[part 1 of 3: packages /MICROSAR/Dem_swc/DataTypes to /MICROSAR/Dem_swc/ComponentTypes]
AUTOSAR XML (schema 00048)
package /MICROSAR/Dem_swc/DataTypes
  25 x impl type:
    Dem_EventIdType: range raw 1..65535, implementation-data-type=uint16
    Dem_RatioIdType: range raw 1..65535, implementation-data-type=uint16
    Dem_DTCStatusMaskType: range raw 0..255, implementation-data-type=uint8
    Dem_OperationCycleIdType: range raw 0..255, implementation-data-type=uint8
    Dem_DTCGroupType: range raw 0..16777215, implementation-data-type=uint32
    Dem_MaxDataValueType: category=ARRAY, sw-calibration-access=READ-ONLY
      element Dem_MaxDataValueTypeElement: array-size=8, array-size-semantics=FIXED-SIZE, implementation-data-type=uint8
    Dem_EventStatusType:
      compu {0=DEM_EVENT_STATUS_PASSED, 1=DEM_EVENT_STATUS_FAILED, 2=DEM_EVENT_STATUS_PREPASSED, 3=DEM_EVENT_STATUS_PREFAILED, 4=DEM_EVENT_STATUS_FDC_THRESHOLD_REACHED, 5=DEM_EVENT_STATUS_PASSED_CONDITIONS_NOT_FULFILLED, 6=DEM_EVENT_STATUS_FAILED_CONDITIONS_NOT_FULFILLED, 7=DEM_EVENT_STATUS_PREPASSED_CONDITIONS_NOT_FULFILLED, 8=DEM_EVENT_STATUS_PREFAILED_CONDITIONS_NOT_FULFILLED}
      range raw 0..255
      implementation-data-type=uint8
    Dem_InitMonitorReasonType: compu {1=DEM_INIT_MONITOR_CLEAR, 2=DEM_INIT_MONITOR_RESTART, 3=DEM_INIT_MONITOR_REENABLED, 4=DEM_INIT_MONITOR_STORAGE_REENABLED}, range raw 1..4, implementation-data-type=uint8
    Dem_DTCOriginType:
      compu {1=DEM_DTC_ORIGIN_PRIMARY_MEMORY, 2=DEM_DTC_ORIGIN_MIRROR_MEMORY, 3=DEM_DTC_ORIGIN_PERMANENT_MEMORY, 4=DEM_DTC_ORIGIN_OBD_RELEVANT_MEMORY, 5=DEM_DTC_ORIGIN_SECONDARY_MEMORY, 5=DEM_DTC_ORIGIN_USERDEFINED_MEMORY_10, 5=DEM_DTC_ORIGIN_USERDEFINED_MEMORY_11, 5=DEM_DTC_ORIGIN_USERDEFINED_MEMORY_12, 5=DEM_DTC_ORIGIN_USERDEFINED_MEMORY_13, 5=DEM_DTC_ORIGIN_USERDEFINED_MEMORY_14, 5=DEM_DTC_ORIGIN_USERDEFINED_MEMORY_15, 5=DEM_DTC_ORIGIN_USERDEFINED_MEMORY_16, 5=DEM_DTC_ORIGIN_USERDEFINED_MEMORY_17, 5=DEM_DTC_ORIGIN_USERDEFINED_MEMORY_18, 5=DEM_DTC_ORIGIN_USERDEFINED_MEMORY_19, 5=DEM_DTC_ORIGIN_USERDEFINED_MEMORY_1A, 5=DEM_DTC_ORIGIN_USERDEFINED_MEMORY_1B, 5=DEM_DTC_ORIGIN_USERDEFINED_MEMORY_1C, 5=DEM_DTC_ORIGIN_USERDEFINED_MEMORY_1D, 5=DEM_DTC_ORIGIN_USERDEFINED_MEMORY_1E, 5=DEM_DTC_ORIGIN_USERDEFINED_MEMORY_1F, 5=DEM_DTC_ORIGIN_USERDEFINED_MEMORY_20, 5=DEM_DTC_ORIGIN_USERDEFINED_MEMORY_21, 5=DEM_DTC_ORIGIN_USERDEFINED_MEMORY_22, 5=DEM_DTC_ORIGIN_USERDEFINED_MEMORY_23, 5=DEM_DTC_ORIGIN_USERDEFINED_MEMORY_24, 5=DEM_DTC_ORIGIN_USERDEFINED_MEMORY_25, 5=DEM_DTC_ORIGIN_USERDEFINED_MEMORY_26, 5=DEM_DTC_ORIGIN_USERDEFINED_MEMORY_27, 5=DEM_DTC_ORIGIN_USERDEFINED_MEMORY_28, 5=DEM_DTC_ORIGIN_USERDEFINED_MEMORY_29, 5=DEM_DTC_ORIGIN_USERDEFINED_MEMORY_2A, 5=DEM_DTC_ORIGIN_USERDEFINED_MEMORY_2B, 5=DEM_DTC_ORIGIN_USERDEFINED_MEMORY_2C, 5=DEM_DTC_ORIGIN_USERDEFINED_MEMORY_2D, 5=DEM_DTC_ORIGIN_USERDEFINED_MEMORY_2E, 5=DEM_DTC_ORIGIN_USERDEFINED_MEMORY_2F, 5=DEM_DTC_ORIGIN_USERDEFINED_MEMORY_30, 5=DEM_DTC_ORIGIN_USERDEFINED_MEMORY_31, 5=DEM_DTC_ORIGIN_USERDEFINED_MEMORY_32, 5=DEM_DTC_ORIGIN_USERDEFINED_MEMORY_33, 5=DEM_DTC_ORIGIN_USERDEFINED_MEMORY_34, 5=DEM_DTC_ORIGIN_USERDEFINED_MEMORY_35, 5=DEM_DTC_ORIGIN_USERDEFINED_MEMORY_36, 5=DEM_DTC_ORIGIN_USERDEFINED_MEMORY_37, 5=DEM_DTC_ORIGIN_USERDEFINED_MEMORY_38, 5=DEM_DTC_ORIGIN_USERDEFINED_MEMORY_39, 5=DEM_DTC_ORIGIN_USERDEFINED_MEMORY_3A, 5=DEM_DTC_ORIGIN_USERDEFINED_MEMORY_3B, 5=DEM_DTC_ORIGIN_USERDEFINED_MEMORY_3C, 5=DEM_DTC_ORIGIN_USERDEFINED_MEMORY_3D, 5=DEM_DTC_ORIGIN_USERDEFINED_MEMORY_3E, 5=DEM_DTC_ORIGIN_USERDEFINED_MEMORY_3F, 5=DEM_DTC_ORIGIN_USERDEFINED_MEMORY_40, 5=DEM_DTC_ORIGIN_USERDEFINED_MEMORY_41, 5=DEM_DTC_ORIGIN_USERDEFINED_MEMORY_42, 5=DEM_DTC_ORIGIN_USERDEFINED_MEMORY_43, 5=DEM_DTC_ORIGIN_USERDEFINED_MEMORY_44, 5=DEM_DTC_ORIGIN_USERDEFINED_MEMORY_45, 5=DEM_DTC_ORIGIN_USERDEFINED_MEMORY_46, 5=DEM_DTC_ORIGIN_USERDEFINED_MEMORY_47, 5=DEM_DTC_ORIGIN_USERDEFINED_MEMORY_48, 5=DEM_DTC_ORIGIN_USERDEFINED_MEMORY_49, 5=DEM_DTC_ORIGIN_USERDEFINED_MEMORY_4A, 5=DEM_DTC_ORIGIN_USERDEFINED_MEMORY_4B, 5=DEM_DTC_ORIGIN_USERDEFINED_MEMORY_4C, 5=DEM_DTC_ORIGIN_USERDEFINED_MEMORY_4D, 5=DEM_DTC_ORIGIN_USERDEFINED_MEMORY_4E, 5=DEM_DTC_ORIGIN_USERDEFINED_MEMORY_4F, 5=DEM_DTC_ORIGIN_USERDEFINED_MEMORY_50, 5=DEM_DTC_ORIGIN_USERDEFINED_MEMORY_51, 5=DEM_DTC_ORIGIN_USERDEFINED_MEMORY_52, 5=DEM_DTC_ORIGIN_USERDEFINED_MEMORY_53, 5=DEM_DTC_ORIGIN_USERDEFINED_MEMORY_54, 5=DEM_DTC_ORIGIN_USERDEFINED_MEMORY_55, 5=DEM_DTC_ORIGIN_USERDEFINED_MEMORY_56, 5=DEM_DTC_ORIGIN_USERDEFINED_MEMORY_57, 5=DEM_DTC_ORIGIN_USERDEFINED_MEMORY_58, 5=DEM_DTC_ORIGIN_USERDEFINED_MEMORY_59, 5=DEM_DTC_ORIGIN_USERDEFINED_MEMORY_5A, 5=DEM_DTC_ORIGIN_USERDEFINED_MEMORY_5B, 5=DEM_DTC_ORIGIN_USERDEFINED_MEMORY_5C, 5=DEM_DTC_ORIGIN_USERDEFINED_MEMORY_5D, 5=DEM_DTC_ORIGIN_USERDEFINED_MEMORY_5E, 5=DEM_DTC_ORIGIN_USERDEFINED_MEMORY_5F, 5=DEM_DTC_ORIGIN_USERDEFINED_MEMORY_60, 5=DEM_DTC_ORIGIN_USERDEFINED_MEMORY_61, 5=DEM_DTC_ORIGIN_USERDEFINED_MEMORY_62, 5=DEM_DTC_ORIGIN_USERDEFINED_MEMORY_63, 5=DEM_DTC_ORIGIN_USERDEFINED_MEMORY_64, 5=DEM_DTC_ORIGIN_USERDEFINED_MEMORY_65, 5=DEM_DTC_ORIGIN_USERDEFINED_MEMORY_66, 5=DEM_DTC_ORIGIN_USERDEFINED_MEMORY_67, 5=DEM_DTC_ORIGIN_USERDEFINED_MEMORY_68, 5=DEM_DTC_ORIGIN_USERDEFINED_MEMORY_69, 5=DEM_DTC_ORIGIN_USERDEFINED_MEMORY_6A, 5=DEM_DTC_ORIGIN_USERDEFINED_MEMORY_6B, 5=DEM_DTC_ORIGIN_USERDEFINED_MEMORY_6C, 5=DEM_DTC_ORIGIN_USERDEFINED_MEMORY_6D, 5=DEM_DTC_ORIGIN_USERDEFINED_MEMORY_6E, 5=DEM_DTC_ORIGIN_USERDEFINED_MEMORY_6F, 5=DEM_DTC_ORIGIN_USERDEFINED_MEMORY_70, 5=DEM_DTC_ORIGIN_USERDEFINED_MEMORY_71, 5=DEM_DTC_ORIGIN_USERDEFINED_MEMORY_72, 5=DEM_DTC_ORIGIN_USERDEFINED_MEMORY_73, 5=DEM_DTC_ORIGIN_USERDEFINED_MEMORY_74, 5=DEM_DTC_ORIGIN_USERDEFINED_MEMORY_75, 5=DEM_DTC_ORIGIN_USERDEFINED_MEMORY_76, 5=DEM_DTC_ORIGIN_USERDEFINED_MEMORY_77, 5=DEM_DTC_ORIGIN_USERDEFINED_MEMORY_78, 5=DEM_DTC_ORIGIN_USERDEFINED_MEMORY_79, 5=DEM_DTC_ORIGIN_USERDEFINED_MEMORY_7A, 5=DEM_DTC_ORIGIN_USERDEFINED_MEMORY_7B, 5=DEM_DTC_ORIGIN_USERDEFINED_MEMORY_7C, 5=DEM_DTC_ORIGIN_USERDEFINED_MEMORY_7D, 5=DEM_DTC_ORIGIN_USERDEFINED_MEMORY_7E, 5=DEM_DTC_ORIGIN_USERDEFINED_MEMORY_7F, 5=DEM_DTC_ORIGIN_USERDEFINED_MEMORY_80, 5=DEM_DTC_ORIGIN_USERDEFINED_MEMORY_81, 5=DEM_DTC_ORIGIN_USERDEFINED_MEMORY_82, 5=DEM_DTC_ORIGIN_USERDEFINED_MEMORY_83, 5=DEM_DTC_ORIGIN_USERDEFINED_MEMORY_84, 5=DEM_DTC_ORIGIN_USERDEFINED_MEMORY_85, 5=DEM_DTC_ORIGIN_USERDEFINED_MEMORY_86, 5=DEM_DTC_ORIGIN_USERDEFINED_MEMORY_87, 5=DEM_DTC_ORIGIN_USERDEFINED_MEMORY_88, 5=DEM_DTC_ORIGIN_USERDEFINED_MEMORY_89, 5=DEM_DTC_ORIGIN_USERDEFINED_MEMORY_8A, 5=DEM_DTC_ORIGIN_USERDEFINED_MEMORY_8B, 5=DEM_DTC_ORIGIN_USERDEFINED_MEMORY_8C, 5=DEM_DTC_ORIGIN_USERDEFINED_MEMORY_8D, 5=DEM_DTC_ORIGIN_USERDEFINED_MEMORY_8E, 5=DEM_DTC_ORIGIN_USERDEFINED_MEMORY_8F, 5=DEM_DTC_ORIGIN_USERDEFINED_MEMORY_90, 5=DEM_DTC_ORIGIN_USERDEFINED_MEMORY_91, 5=DEM_DTC_ORIGIN_USERDEFINED_MEMORY_92, 5=DEM_DTC_ORIGIN_USERDEFINED_MEMORY_93, 5=DEM_DTC_ORIGIN_USERDEFINED_MEMORY_94, 5=DEM_DTC_ORIGIN_USERDEFINED_MEMORY_95, 5=DEM_DTC_ORIGIN_USERDEFINED_MEMORY_96, 5=DEM_DTC_ORIGIN_USERDEFINED_MEMORY_97, 5=DEM_DTC_ORIGIN_USERDEFINED_MEMORY_98, 5=DEM_DTC_ORIGIN_USERDEFINED_MEMORY_99, 5=DEM_DTC_ORIGIN_USERDEFINED_MEMORY_9A, 5=DEM_DTC_ORIGIN_USERDEFINED_MEMORY_9B, 5=DEM_DTC_ORIGIN_USERDEFINED_MEMORY_9C, 5=DEM_DTC_ORIGIN_USERDEFINED_MEMORY_9D, 5=DEM_DTC_ORIGIN_USERDEFINED_MEMORY_9E, 5=DEM_DTC_ORIGIN_USERDEFINED_MEMORY_9F, 5=DEM_DTC_ORIGIN_USERDEFINED_MEMORY_A0, 5=DEM_DTC_ORIGIN_USERDEFINED_MEMORY_A1, 5=DEM_DTC_ORIGIN_USERDEFINED_MEMORY_A2, 5=DEM_DTC_ORIGIN_USERDEFINED_MEMORY_A3, 5=DEM_DTC_ORIGIN_USERDEFINED_MEMORY_A4, 5=DEM_DTC_ORIGIN_USERDEFINED_MEMORY_A5, 5=DEM_DTC_ORIGIN_USERDEFINED_MEMORY_A6, 5=DEM_DTC_ORIGIN_USERDEFINED_MEMORY_A7, 5=DEM_DTC_ORIGIN_USERDEFINED_MEMORY_A8, 5=DEM_DTC_ORIGIN_USERDEFINED_MEMORY_A9, 5=DEM_DTC_ORIGIN_USERDEFINED_MEMORY_AA, 5=DEM_DTC_ORIGIN_USERDEFINED_MEMORY_AB, 5=DEM_DTC_ORIGIN_USERDEFINED_MEMORY_AC, 5=DEM_DTC_ORIGIN_USERDEFINED_MEMORY_AD, 5=DEM_DTC_ORIGIN_USERDEFINED_MEMORY_AE, 5=DEM_DTC_ORIGIN_USERDEFINED_MEMORY_AF, 5=DEM_DTC_ORIGIN_USERDEFINED_MEMORY_B0, 5=DEM_DTC_ORIGIN_USERDEFINED_MEMORY_B1, 5=DEM_DTC_ORIGIN_USERDEFINED_MEMORY_B2, 5=DEM_DTC_ORIGIN_USERDEFINED_MEMORY_B3, 5=DEM_DTC_ORIGIN_USERDEFINED_MEMORY_B4, 5=DEM_DTC_ORIGIN_USERDEFINED_MEMORY_B5, 5=DEM_DTC_ORIGIN_USERDEFINED_MEMORY_B6, 5=DEM_DTC_ORIGIN_USERDEFINED_MEMORY_B7, 5=DEM_DTC_ORIGIN_USERDEFINED_MEMORY_B8, 5=DEM_DTC_ORIGIN_USERDEFINED_MEMORY_B9, 5=DEM_DTC_ORIGIN_USERDEFINED_MEMORY_BA, 5=DEM_DTC_ORIGIN_USERDEFINED_MEMORY_BB, 5=DEM_DTC_ORIGIN_USERDEFINED_MEMORY_BC, 5=DEM_DTC_ORIGIN_USERDEFINED_MEMORY_BD, 5=DEM_DTC_ORIGIN_USERDEFINED_MEMORY_BE, 5=DEM_DTC_ORIGIN_USERDEFINED_MEMORY_BF, 5=DEM_DTC_ORIGIN_USERDEFINED_MEMORY_C0, 5=DEM_DTC_ORIGIN_USERDEFINED_MEMORY_C1, 5=DEM_DTC_ORIGIN_USERDEFINED_MEMORY_C2, 5=DEM_DTC_ORIGIN_USERDEFINED_MEMORY_C3, 5=DEM_DTC_ORIGIN_USERDEFINED_MEMORY_C4, 5=DEM_DTC_ORIGIN_USERDEFINED_MEMORY_C5, 5=DEM_DTC_ORIGIN_USERDEFINED_MEMORY_C6, 5=DEM_DTC_ORIGIN_USERDEFINED_MEMORY_C7, 5=DEM_DTC_ORIGIN_USERDEFINED_MEMORY_C8, 5=DEM_DTC_ORIGIN_USERDEFINED_MEMORY_C9, 5=DEM_DTC_ORIGIN_USERDEFINED_MEMORY_CA, 5=DEM_DTC_ORIGIN_USERDEFINED_MEMORY_CB, 5=DEM_DTC_ORIGIN_USERDEFINED_MEMORY_CC, 5=DEM_DTC_ORIGIN_USERDEFINED_MEMORY_CD, 5=DEM_DTC_ORIGIN_USERDEFINED_MEMORY_CE, 5=DEM_DTC_ORIGIN_USERDEFINED_MEMORY_CF, 5=DEM_DTC_ORIGIN_USERDEFINED_MEMORY_D0, 5=DEM_DTC_ORIGIN_USERDEFINED_MEMORY_D1, 5=DEM_DTC_ORIGIN_USERDEFINED_MEMORY_D2, 5=DEM_DTC_ORIGIN_USERDEFINED_MEMORY_D3, 5=DEM_DTC_ORIGIN_USERDEFINED_MEMORY_D4, 5=DEM_DTC_ORIGIN_USERDEFINED_MEMORY_D5, 5=DEM_DTC_ORIGIN_USERDEFINED_MEMORY_D6, 5=DEM_DTC_ORIGIN_USERDEFINED_MEMORY_D7, 5=DEM_DTC_ORIGIN_USERDEFINED_MEMORY_D8, 5=DEM_DTC_ORIGIN_USERDEFINED_MEMORY_D9, 5=DEM_DTC_ORIGIN_USERDEFINED_MEMORY_DA, 5=DEM_DTC_ORIGIN_USERDEFINED_MEMORY_DB, 5=DEM_DTC_ORIGIN_USERDEFINED_MEMORY_DC, 5=DEM_DTC_ORIGIN_USERDEFINED_MEMORY_DD, 5=DEM_DTC_ORIGIN_USERDEFINED_MEMORY_DE, 5=DEM_DTC_ORIGIN_USERDEFINED_MEMORY_DF, 5=DEM_DTC_ORIGIN_USERDEFINED_MEMORY_E0, 5=DEM_DTC_ORIGIN_USERDEFINED_MEMORY_E1, 5=DEM_DTC_ORIGIN_USERDEFINED_MEMORY_E2, 5=DEM_DTC_ORIGIN_USERDEFINED_MEMORY_E3, 5=DEM_DTC_ORIGIN_USERDEFINED_MEMORY_E4, 5=DEM_DTC_ORIGIN_USERDEFINED_MEMORY_E5, 5=DEM_DTC_ORIGIN_USERDEFINED_MEMORY_E6, 5=DEM_DTC_ORIGIN_USERDEFINED_MEMORY_E7, 5=DEM_DTC_ORIGIN_USERDEFINED_MEMORY_E8, 5=DEM_DTC_ORIGIN_USERDEFINED_MEMORY_E9, 5=DEM_DTC_ORIGIN_USERDEFINED_MEMORY_EA, 5=DEM_DTC_ORIGIN_USERDEFINED_MEMORY_EB, 5=DEM_DTC_ORIGIN_USERDEFINED_MEMORY_EC, 5=DEM_DTC_ORIGIN_USERDEFINED_MEMORY_ED, 5=DEM_DTC_ORIGIN_USERDEFINED_MEMORY_EE, 5=DEM_DTC_ORIGIN_USERDEFINED_MEMORY_EF, 5=DEM_DTC_ORIGIN_USERDEFINED_MEMORY_F0, 5=DEM_DTC_ORIGIN_USERDEFINED_MEMORY_F1, 5=DEM_DTC_ORIGIN_USERDEFINED_MEMORY_F2, 5=DEM_DTC_ORIGIN_USERDEFINED_MEMORY_F3, 5=DEM_DTC_ORIGIN_USERDEFINED_MEMORY_F4, 5=DEM_DTC_ORIGIN_USERDEFINED_MEMORY_F5, 5=DEM_DTC_ORIGIN_USERDEFINED_MEMORY_F6, 5=DEM_DTC_ORIGIN_USERDEFINED_MEMORY_F7, 5=DEM_DTC_ORIGIN_USERDEFINED_MEMORY_F8, 5=DEM_DTC_ORIGIN_USERDEFINED_MEMORY_F9, 5=DEM_DTC_ORIGIN_USERDEFINED_MEMORY_FA, 5=DEM_DTC_ORIGIN_USERDEFINED_MEMORY_FB, 5=DEM_DTC_ORIGIN_USERDEFINED_MEMORY_FC, 5=DEM_DTC_ORIGIN_USERDEFINED_MEMORY_FD, 5=DEM_DTC_ORIGIN_USERDEFINED_MEMORY_FE, 5=DEM_DTC_ORIGIN_USERDEFINED_MEMORY_FF}
      range raw 1..511
      implementation-data-type=uint16
    Dem_DTCFormatType: compu {0=DEM_DTC_FORMAT_OBD, 1=DEM_DTC_FORMAT_UDS, 2=DEM_DTC_FORMAT_J1939}, range raw 0..2, implementation-data-type=uint8
    Dem_OperationCycleStateType: compu {0=DEM_CYCLE_STATE_START, 1=DEM_CYCLE_STATE_END}, range raw 0..1, implementation-data-type=uint8
    Dem_IndicatorStatusType: compu {0=DEM_INDICATOR_OFF, 1=DEM_INDICATOR_CONTINUOUS, 2=DEM_INDICATOR_BLINKING, 3=DEM_INDICATOR_BLINK_CONT, 4=DEM_INDICATOR_SLOW_FLASH, 5=DEM_INDICATOR_FAST_FLASH, 6=DEM_INDICATOR_ON_DEMAND, 7=DEM_INDICATOR_SHORT}, range raw 0..7, implementation-data-type=uint8
    Dem_DTCKindType: compu {1=DEM_DTC_KIND_ALL_DTCS, 2=DEM_DTC_KIND_EMISSION_REL_DTCS}, range raw 0..255, implementation-data-type=uint8
    Dem_IumprDenomCondIdType: compu {1=DEM_IUMPR_GENERAL_DENOMINATOR, 2=DEM_IUMPR_DEN_COND_COLDSTART, 3=DEM_IUMPR_DEN_COND_EVAP, 4=DEM_IUMPR_DEN_COND_500MI, 5=DEM_IUMPR_GENERAL_INDIVIDUAL_DENOMINATOR, 6=DEM_IUMPR_GENERAL_OBDCOND, 7=DEM_IUMPR_DEN_COND_INDEPENDENT}, range raw 0..255, implementation-data-type=uint8
    Dem_IumprDenomCondStatusType: compu {0=DEM_IUMPR_DEN_STATUS_NOT_REACHED, 1=DEM_IUMPR_DEN_STATUS_REACHED, 2=DEM_IUMPR_DEN_STATUS_INHIBITED}, range raw 0..255, implementation-data-type=uint8
    Dem_DebounceResetStatusType: compu {0=DEM_DEBOUNCE_STATUS_FREEZE, 1=DEM_DEBOUNCE_STATUS_RESET}, range raw 0..255, implementation-data-type=uint8
    Dem_IumprReadinessGroupType:
      compu {0=DEM_IUMPR_BOOSTPRS, 1=DEM_IUMPR_CAT1, 2=DEM_IUMPR_CAT2, 3=DEM_IUMPR_EGR, 4=DEM_IUMPR_EGSENSOR, 5=DEM_IUMPR_EVAP, 6=DEM_IUMPR_NMHCCAT, 7=DEM_IUMPR_NOXADSORB, 8=DEM_IUMPR_NOXCAT, 9=DEM_IUMPR_OXS1, 10=DEM_IUMPR_OXS2, 11=DEM_IUMPR_PMFILTER, 12=DEM_IUMPR_PRIVATE, 13=DEM_IUMPR_SAIR, 14=DEM_IUMPR_SECOXS1, 15=DEM_IUMPR_SECOXS2, 16=DEM_IUMPR_FLSYS, 17=DEM_IUMPR_AFRI1, 18=DEM_IUMPR_AFRI2, 19=DEM_IUMPR_PF1, 20=DEM_IUMPR_PF2, 255=DEM_IUMPR_ALLGROUPS}
      range raw 0..255
      implementation-data-type=uint8
    Dem_DTRControlType: compu {0=DEM_DTR_CTL_NORMAL, 1=DEM_DTR_CTL_NO_MAX, 2=DEM_DTR_CTL_NO_MIN, 3=DEM_DTR_CTL_RESET, 4=DEM_DTR_CTL_INVISIBLE}, range raw 0..255, implementation-data-type=uint8
    Dem_DebouncingStateType:
      compu {mask 1: 1=DEM_TEMPORARILY_DEFECTIVE (Bit 0: Temporarily Defective (corresponds to 0 < FDC < 127)), mask 2: 2=DEM_FINALLY_DEFECTIVE (Bit 1: Finally Defective (corresponds to FDC = 127)), mask 4: 4=DEM_TEMPORARILY_HEALED (Bit 2: Temporarily healed (corresponds to -128 < FDC < 0)), mask 8: 8=DEM_TEST_COMPLETE (Bit 3: Test complete (corresponds to FDC = -128 or FDC = 127)), mask 16: 16=DEM_DTR_UPDATE (Bit 4: DTR Update (= Test complete && Debouncing complete && enable conditions / storage conditions fulfilled))}
      range raw 0..255
      implementation-data-type=uint8
    Dem_DTCSeverityType:
      compu {mask 255: 0=DEM_SEVERITY_NO_SEVERITY (DTC_NO_SEVERITY) (No severity information available), mask 31: 1=DEM_SEVERITY_WWHOBD_CLASS_NO_CLASS (DTC_CLASS) (No class information), mask 31: 2=DEM_SEVERITY_WWHOBD_CLASS_A (DTC_CLASS) (WWH-OBD Class A), mask 31: 4=DEM_SEVERITY_WWHOBD_CLASS_B1 (DTC_CLASS) (WWH-OBD Class B1), mask 31: 8=DEM_SEVERITY_WWHOBD_CLASS_B2 (DTC_CLASS) (WWH-OBD Class B2), mask 31: 16=DEM_SEVERITY_WWHOBD_CLASS_C (DTC_CLASS) (WWH-OBD Class C), mask 224: 32=DEM_SEVERITY_MAINTENANCE_ONLY (DTC_SEVERITY) (Maintenance required), mask 224: 64=DEM_SEVERITY_CHECK_AT_NEXT_HALT (DTC_SEVERITY) (Check at next halt), mask 224: 128=DEM_SEVERITY_CHECK_IMMEDIATELY (DTC_SEVERITY) (Check immediately)}
      range raw 0..255
      implementation-data-type=uint8
    Dem_UdsStatusByteType:
      compu {mask 1: 1=DEM_UDS_STATUS_TF (bit 0: TestFailed), mask 2: 2=DEM_UDS_STATUS_TFTOC (bit 1: TestFailedThisOperationCycle), mask 4: 4=DEM_UDS_STATUS_PDTC (bit 2: PendingDTC), mask 8: 8=DEM_UDS_STATUS_CDTC (bit 3: ConfirmedDTC), mask 16: 16=DEM_UDS_STATUS_TNCSLC (bit 4: TestNotCompletedSinceLastClear), mask 32: 32=DEM_UDS_STATUS_TFSLC (bit 5: TestFailedSinceLastClear), mask 64: 64=DEM_UDS_STATUS_TNCTOC (bit 6: TestNotCompletedThisOperationCycle), mask 128: 128=DEM_UDS_STATUS_WIR (bit 7: WarningIndicatorRequested)}
      range raw 0..255
      implementation-data-type=uint8
    Dem_MonitorStatusType: compu {mask 1: 1=DEM_MONITOR_STATUS_TF (bit 0: TestFailed), mask 2: 2=DEM_MONITOR_STATUS_TNCTOC (bit 1: TestNotCompletedThisOperationCycle)}, range raw 0..255, implementation-data-type=uint8
    DataArrayType_uint8_1: category=ARRAY, sw-calibration-access=READ-ONLY
      element DataArrayType_uint8_1Element: array-size=1, array-size-semantics=FIXED-SIZE, implementation-data-type=uint8
    DataArrayType_uint8_2: category=ARRAY, sw-calibration-access=READ-ONLY
      element DataArrayType_uint8_2Element: array-size=2, array-size-semantics=FIXED-SIZE, implementation-data-type=uint8
    DataArrayType_uint8_3: category=ARRAY, sw-calibration-access=READ-ONLY
      element DataArrayType_uint8_3Element: array-size=3, array-size-semantics=FIXED-SIZE, implementation-data-type=uint8
package /MICROSAR/Dem_swc/Interfaces
  38 x client server interface, all with is-service=true, service-kind=DIAGNOSTIC-EVENT-MANAGER:
    DemServices
      operation GetPostRunRequested: possible-error=DemServices/E_NOT_OK
        arg IsRequested: type=boolean, direction=OUT
      operation GetDTCStatusAvailabilityMask: possible-error=DemServices/E_NOT_OK
        arg ClientId: type=uint8, direction=IN
        arg DTCStatusMask: type=uint8, direction=OUT
      error E_NOT_OK: error-code=1
    ClearDTC
      operation ClearDTC: possible-error=[ClearDTC/E_NOT_OK, DEM_CLEAR_FAILED, DEM_PENDING, DEM_CLEAR_BUSY, DEM_CLEAR_MEMORY_ERROR, DEM_WRONG_DTC, DEM_WRONG_DTCORIGIN]
      operation SelectDTC: possible-error=[ClearDTC/E_OK, ClearDTC/E_NOT_OK]
        arg DTC: type=uint32, direction=IN
        arg DTCFormat: type=Dem_DTCFormatType, direction=IN
        arg DTCOrigin: type=Dem_DTCOriginType, direction=IN
      8 x error:
        E_OK: error-code=0
        E_NOT_OK: error-code=1
        DEM_CLEAR_FAILED: error-code=7
        DEM_PENDING: error-code=4
        DEM_CLEAR_BUSY: error-code=5
        DEM_CLEAR_MEMORY_ERROR: error-code=6
        DEM_WRONG_DTC: error-code=8
        DEM_WRONG_DTCORIGIN: error-code=9
    EnableCondition
      operation SetEnableCondition: possible-error=EnableCondition/E_NOT_OK
        arg ConditionFulfilled: type=boolean, direction=IN
      error E_NOT_OK: error-code=1
    IndicatorStatus
      operation GetIndicatorStatus: possible-error=IndicatorStatus/E_NOT_OK
        arg IndicatorStatus: type=Dem_IndicatorStatusType, direction=OUT
      error E_NOT_OK: error-code=1
    EvMemOverflowIndication
      operation GetEventMemoryOverflow: possible-error=EvMemOverflowIndication/E_NOT_OK
        arg OverflowIndication: type=boolean, direction=OUT
      operation GetNumberOfEventMemoryEntries: possible-error=EvMemOverflowIndication/E_NOT_OK
        arg NumberOfEventMemoryEntries: type=uint8, direction=OUT
      error E_NOT_OK: error-code=1
    GeneralDiagnosticInfo
      11 x operation:
        GetEventUdsStatus: possible-error=GeneralDiagnosticInfo/E_NOT_OK
          arg EventId: type=Dem_EventIdType, direction=IN
          arg UDSStatusByte: type=Dem_UdsStatusByteType, direction=OUT
        GetEventStatus: possible-error=GeneralDiagnosticInfo/E_NOT_OK
          arg EventId: type=Dem_EventIdType, direction=IN
          arg UDSStatusByte: type=Dem_UdsStatusByteType, direction=OUT
        GetEventFailed: possible-error=GeneralDiagnosticInfo/E_NOT_OK
          arg EventId: type=Dem_EventIdType, direction=IN
          arg EventFailed: type=boolean, direction=OUT
        GetEventTested: possible-error=GeneralDiagnosticInfo/E_NOT_OK
          arg EventId: type=Dem_EventIdType, direction=IN
          arg EventTested: type=boolean, direction=OUT
        GetDTCOfEvent: possible-error=[GeneralDiagnosticInfo/E_NOT_OK, GeneralDiagnosticInfo/DEM_E_NO_DTC_AVAILABLE]
          arg EventId: type=Dem_EventIdType, direction=IN
          arg DTCFormat: type=Dem_DTCFormatType, direction=IN
          arg DTCOfEvent: type=uint32, direction=OUT
        GetFaultDetectionCounter: possible-error=[GeneralDiagnosticInfo/E_NOT_OK, GeneralDiagnosticInfo/DEM_E_NO_FDC_AVAILABLE]
          arg EventId: type=Dem_EventIdType, direction=IN
          arg FaultDetectionCounter: type=sint8, direction=OUT
        GetEventFreezeFrameDataEx: possible-error=[GeneralDiagnosticInfo/E_NOT_OK, GeneralDiagnosticInfo/DEM_BUFFER_TOO_SMALL, GeneralDiagnosticInfo/DEM_NO_SUCH_ELEMENT]
          5 x arg:
            EventId: type=Dem_EventIdType, direction=IN
            RecordNumber: type=uint8, direction=IN
            DataId: type=uint16, direction=IN
            DestBuffer: type=Dem_MaxDataValueType, direction=OUT
            BufSize: type=uint16, direction=INOUT
        GetEventExtendedDataRecordEx: possible-error=[GeneralDiagnosticInfo/E_NOT_OK, GeneralDiagnosticInfo/DEM_BUFFER_TOO_SMALL, GeneralDiagnosticInfo/DEM_NO_SUCH_ELEMENT]
          4 x arg:
            EventId: type=Dem_EventIdType, direction=IN
            RecordNumber: type=uint8, direction=IN
            DestBuffer: type=Dem_MaxDataValueType, direction=OUT
            BufSize: type=uint16, direction=INOUT
        GetEventEnableCondition: possible-error=GeneralDiagnosticInfo/E_NOT_OK
          arg EventId: type=Dem_EventIdType, direction=IN
          arg ConditionFullfilled: type=boolean, direction=OUT
        GetDebouncingOfEvent: possible-error=GeneralDiagnosticInfo/E_NOT_OK
          arg EventId: type=Dem_EventIdType, direction=IN
          arg DebouncingState: type=Dem_DebouncingStateType, direction=OUT
        GetMonitorStatus: possible-error=GeneralDiagnosticInfo/E_NOT_OK
          arg EventId: type=Dem_EventIdType, direction=IN
          arg MonitorStatus: type=Dem_MonitorStatusType, direction=OUT
      5 x error:
        E_NOT_OK: error-code=1
        DEM_E_NO_DTC_AVAILABLE: error-code=10
        DEM_E_NO_FDC_AVAILABLE: error-code=14
        DEM_BUFFER_TOO_SMALL: error-code=21
        DEM_NO_SUCH_ELEMENT: error-code=48
    OperationCycle
      operation GetOperationCycleState: possible-error=[OperationCycle/E_OK, OperationCycle/E_NOT_OK]
        arg CycleState: type=Dem_OperationCycleStateType, direction=OUT
      operation SetOperationCycleState: possible-error=[OperationCycle/E_OK, OperationCycle/E_NOT_OK]
        arg CycleState: type=Dem_OperationCycleStateType, direction=IN
      error E_OK: error-code=0
      error E_NOT_OK: error-code=1
    CSDataServices_DID_0xf1a4_Date_And_Time_Minute
      operation ReadData: possible-error=CSDataServices_DID_0xf1a4_Date_And_Time_Minute/E_NOT_OK
        arg Data: type=DataArrayType_uint8_1, direction=OUT
      error E_NOT_OK: error-code=1
    CSDataServices_DID_0xf1a0_Ignition_Switch_Signal
      operation ReadData: possible-error=CSDataServices_DID_0xf1a0_Ignition_Switch_Signal/E_NOT_OK
        arg Data: type=DataArrayType_uint8_1, direction=OUT
      error E_NOT_OK: error-code=1
    CSDataServices_DID_0x1d01_Accelerator_pedal_sensor_2_voltage
      operation ReadData: possible-error=CSDataServices_DID_0x1d01_Accelerator_pedal_sensor_2_voltage/E_NOT_OK
        arg Data: type=DataArrayType_uint8_1, direction=OUT
      error E_NOT_OK: error-code=1
    CSDataServices_DID_0x1d11_Mainrealy1
      operation ReadData: possible-error=CSDataServices_DID_0x1d11_Mainrealy1/E_NOT_OK
        arg Data: type=DataArrayType_uint8_1, direction=OUT
      error E_NOT_OK: error-code=1
    CSDataServices_DID_0x1d05_POD_OBC_OutputDCChargeCurrent
      operation ReadData: possible-error=CSDataServices_DID_0x1d05_POD_OBC_OutputDCChargeCurrent/E_NOT_OK
        arg Data: type=DataArrayType_uint8_2, direction=OUT
      error E_NOT_OK: error-code=1
    CSDataServices_DID_0x1d01_Accelerator_pedal_sensor_1_voltage
      operation ReadData: possible-error=CSDataServices_DID_0x1d01_Accelerator_pedal_sensor_1_voltage/E_NOT_OK
        arg Data: type=DataArrayType_uint8_1, direction=OUT
      error E_NOT_OK: error-code=1
    CSDataServices_DID_0x1d07_Electronic_lock_state
      operation ReadData: possible-error=CSDataServices_DID_0x1d07_Electronic_lock_state/E_NOT_OK
        arg Data: type=DataArrayType_uint8_1, direction=OUT
      error E_NOT_OK: error-code=1
    CSDataServices_DID_0x1d09_New_Bit_Field
      operation ReadData: possible-error=CSDataServices_DID_0x1d09_New_Bit_Field/E_NOT_OK
        arg Data: type=DataArrayType_uint8_1, direction=OUT
      error E_NOT_OK: error-code=1
    CSDataServices_DID_0x1d01_VCU_VehicleSpeed
      operation ReadData: possible-error=CSDataServices_DID_0x1d01_VCU_VehicleSpeed/E_NOT_OK
        arg Data: type=DataArrayType_uint8_2, direction=OUT
      error E_NOT_OK: error-code=1
    CSDataServices_DID_0xf1a3_Vehicle_speed
      operation ReadData: possible-error=CSDataServices_DID_0xf1a3_Vehicle_speed/E_NOT_OK
        arg Data: type=DataArrayType_uint8_2, direction=OUT
      error E_NOT_OK: error-code=1
    CSDataServices_DID_0x1d05_POD_OBC_InputACVoltage
      operation ReadData: possible-error=CSDataServices_DID_0x1d05_POD_OBC_InputACVoltage/E_NOT_OK
        arg Data: type=DataArrayType_uint8_2, direction=OUT
      error E_NOT_OK: error-code=1
    CSDataServices_DID_0xf1a2_Total_Odometer
      operation ReadData: possible-error=CSDataServices_DID_0xf1a2_Total_Odometer/E_NOT_OK
        arg Data: type=DataArrayType_uint8_3, direction=OUT
      error E_NOT_OK: error-code=1
    CSDataServices_DID_0xf1a5_VCU_HVStatus
      operation ReadData: possible-error=CSDataServices_DID_0xf1a5_VCU_HVStatus/E_NOT_OK
        arg Data: type=DataArrayType_uint8_1, direction=OUT
      error E_NOT_OK: error-code=1
    CSDataServices_DID_0xf1a7_Gear
      operation ReadData: possible-error=CSDataServices_DID_0xf1a7_Gear/E_NOT_OK
        arg Data: type=DataArrayType_uint8_1, direction=OUT
      error E_NOT_OK: error-code=1
    CSDataServices_ExtendedData_Fault_Aging_Counter
      operation ReadData: possible-error=CSDataServices_ExtendedData_Fault_Aging_Counter/E_NOT_OK
        arg Data: type=DataArrayType_uint8_1, direction=OUT
      error E_NOT_OK: error-code=1
    CSDataServices_DID_0xf1a1_Battery_Voltage
      operation ReadData: possible-error=CSDataServices_DID_0xf1a1_Battery_Voltage/E_NOT_OK
        arg Data: type=DataArrayType_uint8_2, direction=OUT
      error E_NOT_OK: error-code=1
    CSDataServices_DID_0xf1a4_Date_And_Time_Hour
      operation ReadData: possible-error=CSDataServices_DID_0xf1a4_Date_And_Time_Hour/E_NOT_OK
        arg Data: type=DataArrayType_uint8_1, direction=OUT
      error E_NOT_OK: error-code=1
    CSDataServices_DID_0xf1a4_Date_And_Time_Day
      operation ReadData: possible-error=CSDataServices_DID_0xf1a4_Date_And_Time_Day/E_NOT_OK
        arg Data: type=DataArrayType_uint8_1, direction=OUT
      error E_NOT_OK: error-code=1
    CSDataServices_DID_0x1d01_VCU_AccelerationPedal
      operation ReadData: possible-error=CSDataServices_DID_0x1d01_VCU_AccelerationPedal/E_NOT_OK
        arg Data: type=DataArrayType_uint8_1, direction=OUT
      error E_NOT_OK: error-code=1
    CSDataServices_DID_0x1d05_POD_OBC_OutputDCChargeVoltage
      operation ReadData: possible-error=CSDataServices_DID_0x1d05_POD_OBC_OutputDCChargeVoltage/E_NOT_OK
        arg Data: type=DataArrayType_uint8_2, direction=OUT
      error E_NOT_OK: error-code=1
    CSDataServices_ExtendedData_Fault_Ocurrence_Counter
      operation ReadData: possible-error=CSDataServices_ExtendedData_Fault_Ocurrence_Counter/E_NOT_OK
        arg Data: type=DataArrayType_uint8_1, direction=OUT
      error E_NOT_OK: error-code=1
    CSDataServices_DID_0x1d08_VCU_HVIL
      operation ReadData: possible-error=CSDataServices_DID_0x1d08_VCU_HVIL/E_NOT_OK
        arg Data: type=DataArrayType_uint8_1, direction=OUT
      error E_NOT_OK: error-code=1
    CSDataServices_DID_0xf1a4_Date_And_Time_Year
      operation ReadData: possible-error=CSDataServices_DID_0xf1a4_Date_And_Time_Year/E_NOT_OK
        arg Data: type=DataArrayType_uint8_1, direction=OUT
      error E_NOT_OK: error-code=1
    CSDataServices_DID_0xf1a4_Date_And_Time_Month
      operation ReadData: possible-error=CSDataServices_DID_0xf1a4_Date_And_Time_Month/E_NOT_OK
        arg Data: type=DataArrayType_uint8_1, direction=OUT
      error E_NOT_OK: error-code=1
    CSDataServices_DID_0xf1a4_Date_And_Time_Second
      operation ReadData: possible-error=CSDataServices_DID_0xf1a4_Date_And_Time_Second/E_NOT_OK
        arg Data: type=DataArrayType_uint8_1, direction=OUT
      error E_NOT_OK: error-code=1
    CSDataServices_DID_0x1d11_Mainrelay2
      operation ReadData: possible-error=CSDataServices_DID_0x1d11_Mainrelay2/E_NOT_OK
        arg Data: type=DataArrayType_uint8_1, direction=OUT
      error E_NOT_OK: error-code=1
    CSDataServices_ExtendedData_Fault_Aged_Counter
      operation ReadData: possible-error=CSDataServices_ExtendedData_Fault_Aged_Counter/E_NOT_OK
        arg Data: type=DataArrayType_uint8_1, direction=OUT
      error E_NOT_OK: error-code=1
    CSDataServices_DID_0x1d05_VCU_OBC_ChargeCurrentCommand
      operation ReadData: possible-error=CSDataServices_DID_0x1d05_VCU_OBC_ChargeCurrentCommand/E_NOT_OK
        arg Data: type=DataArrayType_uint8_2, direction=OUT
      error E_NOT_OK: error-code=1
    CSDataServices_DID_0xf1a6_SOC
      operation ReadData: possible-error=CSDataServices_DID_0xf1a6_SOC/E_NOT_OK
        arg Data: type=DataArrayType_uint8_2, direction=OUT
      error E_NOT_OK: error-code=1
    DiagnosticInfo
      11 x operation:
        GetEventUdsStatus: possible-error=DiagnosticInfo/E_NOT_OK
          arg UDSStatusByte: type=Dem_UdsStatusByteType, direction=OUT
        GetEventStatus: possible-error=DiagnosticInfo/E_NOT_OK
          arg UDSStatusByte: type=Dem_UdsStatusByteType, direction=OUT
        GetEventFailed: possible-error=DiagnosticInfo/E_NOT_OK
          arg EventFailed: type=boolean, direction=OUT
        GetEventTested: possible-error=DiagnosticInfo/E_NOT_OK
          arg EventTested: type=boolean, direction=OUT
        GetDTCOfEvent: possible-error=[DiagnosticInfo/E_NOT_OK, DiagnosticInfo/DEM_E_NO_DTC_AVAILABLE]
          arg DTCFormat: type=Dem_DTCFormatType, direction=IN
          arg DTCOfEvent: type=uint32, direction=OUT
        GetFaultDetectionCounter: possible-error=[DiagnosticInfo/E_NOT_OK, DiagnosticInfo/DEM_E_NO_FDC_AVAILABLE]
          arg FaultDetectionCounter: type=sint8, direction=OUT
        GetEventFreezeFrameDataEx: possible-error=[DiagnosticInfo/E_NOT_OK, DiagnosticInfo/DEM_BUFFER_TOO_SMALL, DiagnosticInfo/DEM_NO_SUCH_ELEMENT]
          4 x arg:
            RecordNumber: type=uint8, direction=IN
            DataId: type=uint16, direction=IN
            DestBuffer: type=Dem_MaxDataValueType, direction=OUT
            BufSize: type=uint16, direction=INOUT
        GetEventExtendedDataRecordEx: possible-error=[DiagnosticInfo/E_NOT_OK, DiagnosticInfo/DEM_BUFFER_TOO_SMALL, DiagnosticInfo/DEM_NO_SUCH_ELEMENT]
          arg RecordNumber: type=uint8, direction=IN
          arg DestBuffer: type=Dem_MaxDataValueType, direction=OUT
          arg BufSize: type=uint16, direction=INOUT
        GetEventEnableCondition: possible-error=DiagnosticInfo/E_NOT_OK
          arg ConditionFullfilled: type=boolean, direction=OUT
        GetDebouncingOfEvent: possible-error=DiagnosticInfo/E_NOT_OK
          arg DebouncingState: type=Dem_DebouncingStateType, direction=OUT
        GetMonitorStatus: possible-error=DiagnosticInfo/E_NOT_OK
          arg MonitorStatus: type=Dem_MonitorStatusType, direction=OUT
      5 x error:
        E_NOT_OK: error-code=1
        DEM_E_NO_DTC_AVAILABLE: error-code=10
        DEM_E_NO_FDC_AVAILABLE: error-code=14
        DEM_BUFFER_TOO_SMALL: error-code=21
        DEM_NO_SUCH_ELEMENT: error-code=48
    DiagnosticMonitor
      11 x operation:
        SetEventStatus: possible-error=DiagnosticMonitor/E_NOT_OK
          arg EventStatus: type=Dem_EventStatusType, direction=IN
        ResetEventStatus: possible-error=DiagnosticMonitor/E_NOT_OK
        ResetEventDebounceStatus: possible-error=DiagnosticMonitor/E_NOT_OK
          arg DebounceResetStatus: type=Dem_DebounceResetStatusType, direction=IN
        GetEventUdsStatus: possible-error=DiagnosticMonitor/E_NOT_OK
          arg UDSStatusByte: type=Dem_UdsStatusByteType, direction=OUT
        GetEventStatus: possible-error=DiagnosticMonitor/E_NOT_OK
          arg UDSStatusByte: type=Dem_UdsStatusByteType, direction=OUT
        GetEventFailed: possible-error=DiagnosticMonitor/E_NOT_OK
          arg EventFailed: type=boolean, direction=OUT
        GetEventTested: possible-error=DiagnosticMonitor/E_NOT_OK
          arg EventTested: type=boolean, direction=OUT
        GetDTCOfEvent: possible-error=[DiagnosticMonitor/E_NOT_OK, DiagnosticMonitor/DEM_E_NO_DTC_AVAILABLE]
          arg DTCFormat: type=Dem_DTCFormatType, direction=IN
          arg DTCOfEvent: type=uint32, direction=OUT
        GetFaultDetectionCounter: possible-error=[DiagnosticMonitor/E_NOT_OK, DiagnosticMonitor/DEM_E_NO_FDC_AVAILABLE]
          arg FaultDetectionCounter: type=sint8, direction=OUT
        GetEventFreezeFrameDataEx: possible-error=[DiagnosticMonitor/E_NOT_OK, DiagnosticMonitor/DEM_BUFFER_TOO_SMALL, DiagnosticMonitor/DEM_NO_SUCH_ELEMENT]
          4 x arg:
            RecordNumber: type=uint8, direction=IN
            DataId: type=uint16, direction=IN
            DestBuffer: type=Dem_MaxDataValueType, direction=OUT
            BufSize: type=uint16, direction=INOUT
        GetEventExtendedDataRecordEx: possible-error=[DiagnosticMonitor/E_NOT_OK, DiagnosticMonitor/DEM_BUFFER_TOO_SMALL, DiagnosticMonitor/DEM_NO_SUCH_ELEMENT]
          arg RecordNumber: type=uint8, direction=IN
          arg DestBuffer: type=Dem_MaxDataValueType, direction=OUT
          arg BufSize: type=uint16, direction=INOUT
      5 x error:
        E_NOT_OK: error-code=1
        DEM_E_NO_DTC_AVAILABLE: error-code=10
        DEM_E_NO_FDC_AVAILABLE: error-code=14
        DEM_BUFFER_TOO_SMALL: error-code=21
        DEM_NO_SUCH_ELEMENT: error-code=48
package /MICROSAR/Dem_swc/ComponentTypes
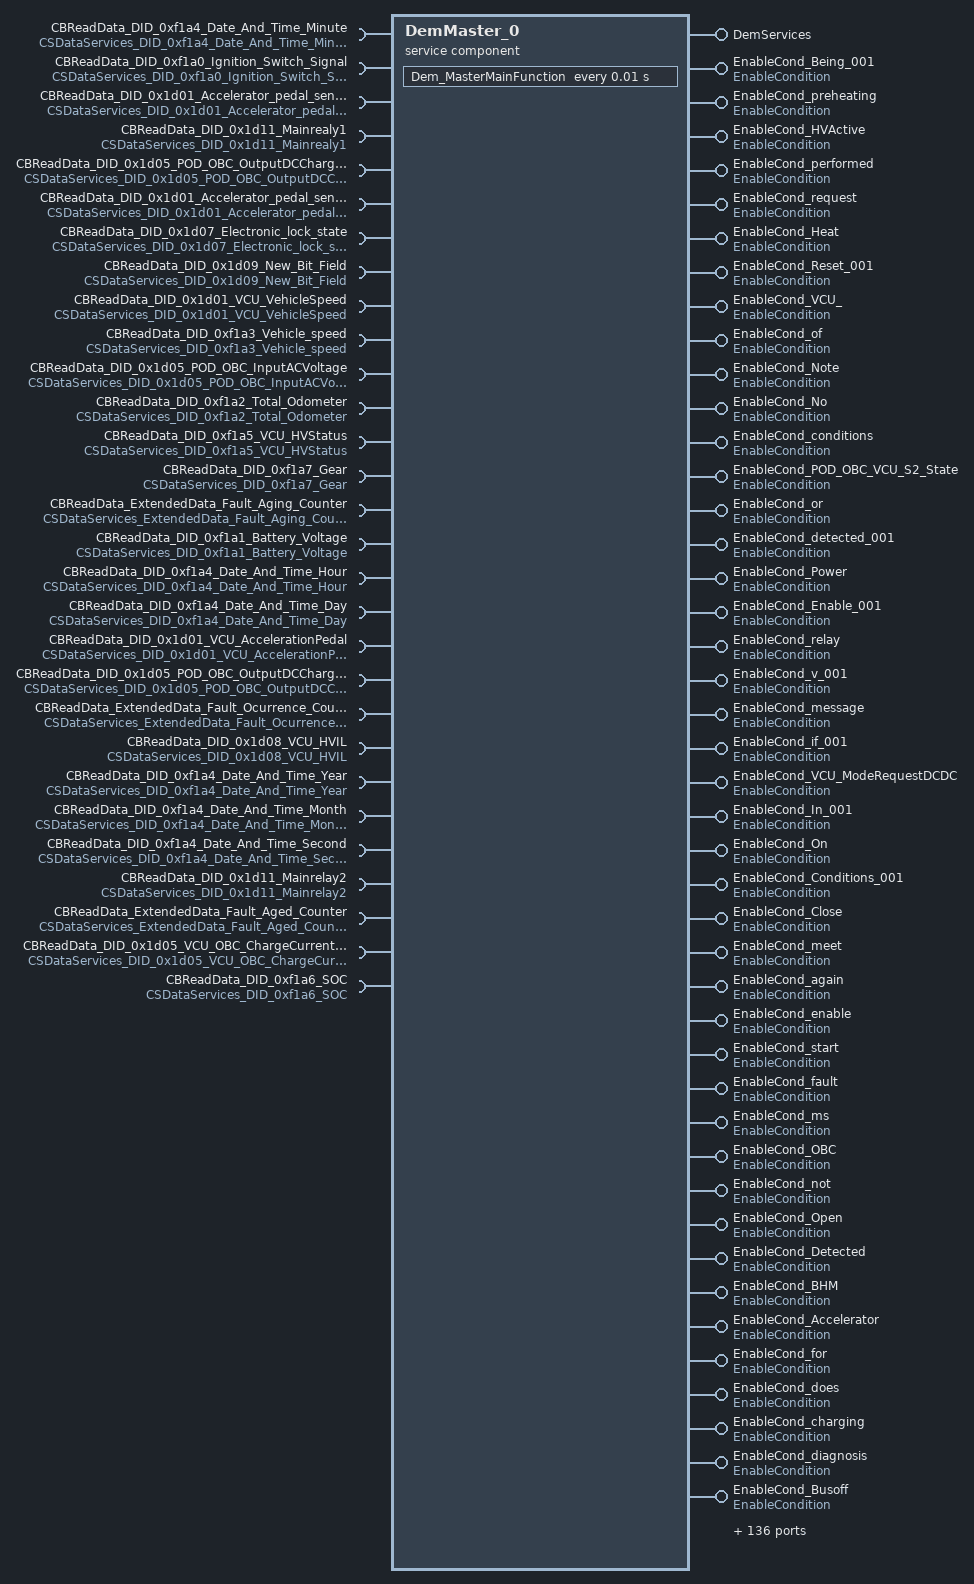
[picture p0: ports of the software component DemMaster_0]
  service sw component type DemMaster_0: category=SERVICE_COMPONENT
    180 x provide port:
      DemServices: provided-interface=DemServices
      EnableCond_Being_001: provided-interface=EnableCondition
      EnableCond_preheating: provided-interface=EnableCondition
      EnableCond_HVActive: provided-interface=EnableCondition
      EnableCond_performed: provided-interface=EnableCondition
      EnableCond_request: provided-interface=EnableCondition
      EnableCond_Heat: provided-interface=EnableCondition
      EnableCond_Reset_001: provided-interface=EnableCondition
      EnableCond_VCU_: provided-interface=EnableCondition
      EnableCond_of: provided-interface=EnableCondition
      EnableCond_Note: provided-interface=EnableCondition
      EnableCond_No: provided-interface=EnableCondition
      EnableCond_conditions: provided-interface=EnableCondition
      EnableCond_POD_OBC_VCU_S2_State: provided-interface=EnableCondition
      EnableCond_or: provided-interface=EnableCondition
      EnableCond_detected_001: provided-interface=EnableCondition
      EnableCond_Power: provided-interface=EnableCondition
      EnableCond_Enable_001: provided-interface=EnableCondition
      EnableCond_relay: provided-interface=EnableCondition
      EnableCond_v_001: provided-interface=EnableCondition
      EnableCond_message: provided-interface=EnableCondition
      EnableCond_if_001: provided-interface=EnableCondition
      EnableCond_VCU_ModeRequestDCDC: provided-interface=EnableCondition
      EnableCond_In_001: provided-interface=EnableCondition
      EnableCond_On: provided-interface=EnableCondition
      EnableCond_Conditions_001: provided-interface=EnableCondition
      EnableCond_Close: provided-interface=EnableCondition
      EnableCond_meet: provided-interface=EnableCondition
      EnableCond_again: provided-interface=EnableCondition
      EnableCond_enable: provided-interface=EnableCondition
      EnableCond_start: provided-interface=EnableCondition
      EnableCond_fault: provided-interface=EnableCondition
      EnableCond_ms: provided-interface=EnableCondition
      EnableCond_OBC: provided-interface=EnableCondition
      EnableCond_not: provided-interface=EnableCondition
      EnableCond_Open: provided-interface=EnableCondition
      EnableCond_Detected: provided-interface=EnableCondition
      EnableCond_BHM: provided-interface=EnableCondition
      EnableCond_Accelerator: provided-interface=EnableCondition
      EnableCond_for: provided-interface=EnableCondition
      EnableCond_does: provided-interface=EnableCondition
      EnableCond_charging: provided-interface=EnableCondition
      EnableCond_diagnosis: provided-interface=EnableCondition
      EnableCond_Busoff: provided-interface=EnableCondition
      EnableCond_last: provided-interface=EnableCondition
      EnableCond_be: provided-interface=EnableCondition
      EnableCond_recovered: provided-interface=EnableCondition
      EnableCond_DTC: provided-interface=EnableCondition
      EnableCond_VCU_OBC_Control_of_em_lock: provided-interface=EnableCondition
      EnableCond_PNC31: provided-interface=EnableCondition
      EnableCond_shall: provided-interface=EnableCondition
      EnableCond_all: provided-interface=EnableCondition
      EnableCond_pin: provided-interface=EnableCondition
      EnableCond_normal: provided-interface=EnableCondition
      EnableCond_Ohm: provided-interface=EnableCondition
      EnableCond_abnormal: provided-interface=EnableCondition
      EnableCond_PNC25: provided-interface=EnableCondition
      EnableCond_the_001: provided-interface=EnableCondition
      EnableCond_VCU_Hvstatus_001: provided-interface=EnableCondition
      EnableCond_DC: provided-interface=EnableCondition
      EnableCond_to: provided-interface=EnableCondition
      EnableCond_Lan: provided-interface=EnableCondition
      EnableCond_requests: provided-interface=EnableCondition
      EnableCond_PNC0: provided-interface=EnableCondition
      EnableCond_PNC13: provided-interface=EnableCondition
      EnableCond_following: provided-interface=EnableCondition
      EnableCond_BMS: provided-interface=EnableCondition
      EnableCond_PNC15: provided-interface=EnableCondition
      EnableCond_PNC14: provided-interface=EnableCondition
      EnableCond_PNC16: provided-interface=EnableCondition
      EnableCond_PNC18: provided-interface=EnableCondition
      EnableCond_All_001: provided-interface=EnableCondition
      EnableCond_signal: provided-interface=EnableCondition
      EnableCond_T_Delay: provided-interface=EnableCondition
      EnableCond_status: provided-interface=EnableCondition
      EnableCond_voltage: provided-interface=EnableCondition
      EnableCond_Request_001: provided-interface=EnableCondition
      EnableCond_BMS_ChargeStatus: provided-interface=EnableCondition
      EnableCond_AC: provided-interface=EnableCondition
      EnableCond_accelerator_001: provided-interface=EnableCondition
      EnableCond_after: provided-interface=EnableCondition
      EnableCond_KL15E_001: provided-interface=EnableCondition
      EnableCond_PNC04: provided-interface=EnableCondition
      EnableCond_PNC03: provided-interface=EnableCondition
      EnableCond_VCU: provided-interface=EnableCondition
      EnableCond_positive: provided-interface=EnableCondition
      EnableCond_S2: provided-interface=EnableCondition
      EnableCond_VCU_RequestedModeTCU: provided-interface=EnableCondition
      EnableCond_Control: provided-interface=EnableCondition
      EnableCond_being: provided-interface=EnableCondition
      EnableCond_POD_OBC_CCStatus: provided-interface=EnableCondition
      EnableCond_switch: provided-interface=EnableCondition
      EnableCond_VCU_EnableOBC: provided-interface=EnableCondition
      EnableCond_VCU_RequestedModeBMS: provided-interface=EnableCondition
      EnableCond_TrqCtrl: provided-interface=EnableCondition
      EnableCond_POD: provided-interface=EnableCondition
      EnableCond_function: provided-interface=EnableCondition
      EnableCond_KL15eWakeUp: provided-interface=EnableCondition
      EnableCond_service: provided-interface=EnableCondition
      EnableCond_pin1: provided-interface=EnableCondition
      EnableCond_pin2: provided-interface=EnableCondition
      EnableCond_Init: provided-interface=EnableCondition
      EnableCond_close_001: provided-interface=EnableCondition
      EnableCond_completed: provided-interface=EnableCondition
      EnableCond_closed: provided-interface=EnableCondition
      EnableCond_disconnect: provided-interface=EnableCondition
      EnableCond_lock: provided-interface=EnableCondition
      EnableCond_VCU_ChargeStatus: provided-interface=EnableCondition
      EnableCond_guns: provided-interface=EnableCondition
      EnableCond_VCU_Enable_DC_Relay: provided-interface=EnableCondition
      EnableCond_BRM: provided-interface=EnableCondition
      EnableCond_ON_001: provided-interface=EnableCondition
      EnableCond_electronic: provided-interface=EnableCondition
      EnableCond_VCU_MCURequestedState: provided-interface=EnableCondition
      EnableCond_do: provided-interface=EnableCondition
      EnableCond_Charging_001: provided-interface=EnableCondition
      EnableCond_negative: provided-interface=EnableCondition
      EnableCond_any: provided-interface=EnableCondition
      EnableCond_recovers: provided-interface=EnableCondition
      EnableCond_condition: provided-interface=EnableCondition
      EnableCond_Confirmed: provided-interface=EnableCondition
      EnableCond_When: provided-interface=EnableCondition
      EnableCond_up: provided-interface=EnableCondition
      EnableCond_met: provided-interface=EnableCondition
      EnableCond_and: provided-interface=EnableCondition
      EnableCond_timing: provided-interface=EnableCondition
      EnableCond_Disable: provided-interface=EnableCondition
      EnableCond_x0: provided-interface=EnableCondition
      EnableCond_x1: provided-interface=EnableCondition
      EnableCond_reset: provided-interface=EnableCondition
      EnableCond_ModeRequestDCDC: provided-interface=EnableCondition
      EnableCond_BMS_status: provided-interface=EnableCondition
      EnableCond_active: provided-interface=EnableCondition
      EnableCond_requirements: provided-interface=EnableCondition
      EnableCond_pedal: provided-interface=EnableCondition
      EnableCond_x4: provided-interface=EnableCondition
      EnableCond_Standby: provided-interface=EnableCondition
      EnableCond_x5: provided-interface=EnableCondition
      EnableCond_x2: provided-interface=EnableCondition
      EnableCond_x3: provided-interface=EnableCondition
      EnableCond_timer: provided-interface=EnableCondition
      EnableCond_criteria: provided-interface=EnableCondition
      EnableCond_times: provided-interface=EnableCondition
      EnableCond_Non: provided-interface=EnableCondition
      EnableCond_confirmation: provided-interface=EnableCondition
      EnableCond_trigger: provided-interface=EnableCondition
      EnableCond_simultaneously: provided-interface=EnableCondition
      EnableCond_InActive: provided-interface=EnableCondition
      EnableCond_battery: provided-interface=EnableCondition
      EnableCond_main: provided-interface=EnableCondition
      EnableCond_from: provided-interface=EnableCondition
      EnableCond_Plug: provided-interface=EnableCondition
      EnableCond_waked: provided-interface=EnableCondition
      EnableCond_charge: provided-interface=EnableCondition
      EnableCond_process: provided-interface=EnableCondition
      EnableCond_Chargestatus: provided-interface=EnableCondition
      EnableCond_during: provided-interface=EnableCondition
      EnableCond_KL15e: provided-interface=EnableCondition
      EnableCond_only: provided-interface=EnableCondition
      EnableCond_MCU_VCUWorkMode: provided-interface=EnableCondition
      EnableCond_High: provided-interface=EnableCondition
      EnableCond_Torque: provided-interface=EnableCondition
      EnableCond_V: provided-interface=EnableCondition
      EnableCond_serviceNote: provided-interface=EnableCondition
      EnableCond_VCU_BMS_Control_of_NegRelay: provided-interface=EnableCondition
      EnableCond_sends: provided-interface=EnableCondition
      EnableCond_opening: provided-interface=EnableCondition
      EnableCond_LAN_001: provided-interface=EnableCondition
      EnableCond_in: provided-interface=EnableCondition
      EnableCond_Ready: provided-interface=EnableCondition
      EnableCond_Buck: provided-interface=EnableCondition
      EnableCond_are: provided-interface=EnableCondition
      EnableCond_is: provided-interface=EnableCondition
      EnableCond_The: provided-interface=EnableCondition
      EnableCond_s: provided-interface=EnableCondition
      EnableCond_If: provided-interface=EnableCondition
      EnableCond_restored: provided-interface=EnableCondition
      IndStatus_WarningIndicator: provided-interface=IndicatorStatus
      GeneralEvtInfo: provided-interface=GeneralDiagnosticInfo
      OpCycle_PowerCycle: provided-interface=OperationCycle
    29 x require port:
      CBReadData_DID_0xf1a4_Date_And_Time_Minute: required-interface=CSDataServices_DID_0xf1a4_Date_And_Time_Minute
      CBReadData_DID_0xf1a0_Ignition_Switch_Signal: required-interface=CSDataServices_DID_0xf1a0_Ignition_Switch_Signal
      CBReadData_DID_0x1d01_Accelerator_pedal_sensor_2_voltage: required-interface=CSDataServices_DID_0x1d01_Accelerator_pedal_sensor_2_voltage
      CBReadData_DID_0x1d11_Mainrealy1: required-interface=CSDataServices_DID_0x1d11_Mainrealy1
      CBReadData_DID_0x1d05_POD_OBC_OutputDCChargeCurrent: required-interface=CSDataServices_DID_0x1d05_POD_OBC_OutputDCChargeCurrent
      CBReadData_DID_0x1d01_Accelerator_pedal_sensor_1_voltage: required-interface=CSDataServices_DID_0x1d01_Accelerator_pedal_sensor_1_voltage
      CBReadData_DID_0x1d07_Electronic_lock_state: required-interface=CSDataServices_DID_0x1d07_Electronic_lock_state
      CBReadData_DID_0x1d09_New_Bit_Field: required-interface=CSDataServices_DID_0x1d09_New_Bit_Field
      CBReadData_DID_0x1d01_VCU_VehicleSpeed: required-interface=CSDataServices_DID_0x1d01_VCU_VehicleSpeed
      CBReadData_DID_0xf1a3_Vehicle_speed: required-interface=CSDataServices_DID_0xf1a3_Vehicle_speed
      CBReadData_DID_0x1d05_POD_OBC_InputACVoltage: required-interface=CSDataServices_DID_0x1d05_POD_OBC_InputACVoltage
      CBReadData_DID_0xf1a2_Total_Odometer: required-interface=CSDataServices_DID_0xf1a2_Total_Odometer
      CBReadData_DID_0xf1a5_VCU_HVStatus: required-interface=CSDataServices_DID_0xf1a5_VCU_HVStatus
      CBReadData_DID_0xf1a7_Gear: required-interface=CSDataServices_DID_0xf1a7_Gear
      CBReadData_ExtendedData_Fault_Aging_Counter: required-interface=CSDataServices_ExtendedData_Fault_Aging_Counter
      CBReadData_DID_0xf1a1_Battery_Voltage: required-interface=CSDataServices_DID_0xf1a1_Battery_Voltage
      CBReadData_DID_0xf1a4_Date_And_Time_Hour: required-interface=CSDataServices_DID_0xf1a4_Date_And_Time_Hour
      CBReadData_DID_0xf1a4_Date_And_Time_Day: required-interface=CSDataServices_DID_0xf1a4_Date_And_Time_Day
      CBReadData_DID_0x1d01_VCU_AccelerationPedal: required-interface=CSDataServices_DID_0x1d01_VCU_AccelerationPedal
      CBReadData_DID_0x1d05_POD_OBC_OutputDCChargeVoltage: required-interface=CSDataServices_DID_0x1d05_POD_OBC_OutputDCChargeVoltage
      CBReadData_ExtendedData_Fault_Ocurrence_Counter: required-interface=CSDataServices_ExtendedData_Fault_Ocurrence_Counter
      CBReadData_DID_0x1d08_VCU_HVIL: required-interface=CSDataServices_DID_0x1d08_VCU_HVIL
      CBReadData_DID_0xf1a4_Date_And_Time_Year: required-interface=CSDataServices_DID_0xf1a4_Date_And_Time_Year
      CBReadData_DID_0xf1a4_Date_And_Time_Month: required-interface=CSDataServices_DID_0xf1a4_Date_And_Time_Month
      CBReadData_DID_0xf1a4_Date_And_Time_Second: required-interface=CSDataServices_DID_0xf1a4_Date_And_Time_Second
      CBReadData_DID_0x1d11_Mainrelay2: required-interface=CSDataServices_DID_0x1d11_Mainrelay2
      CBReadData_ExtendedData_Fault_Aged_Counter: required-interface=CSDataServices_ExtendedData_Fault_Aged_Counter
      CBReadData_DID_0x1d05_VCU_OBC_ChargeCurrentCommand: required-interface=CSDataServices_DID_0x1d05_VCU_OBC_ChargeCurrentCommand
      CBReadData_DID_0xf1a6_SOC: required-interface=CSDataServices_DID_0xf1a6_SOC
    behavior DemMaster_0InternalBehavior: handle-termination-and-restart=NO-SUPPORT, included-data-type-set=data-type=[Dem_EventIdType, Dem_RatioIdType, Dem_EventStatusType, Dem_UdsStatusByteType, Dem_DTCFormatType, Dem_InitMonitorReasonType, Dem_OperationCycleStateType, Dem_DTCStatusMaskType, Dem_IndicatorStatusType, Dem_MaxDataValueType, Dem_DTCKindType, Dem_DTCGroupType, Dem_IumprDenomCondIdType, Dem_IumprDenomCondStatusType, Dem_DebounceResetStatusType, Dem_DebouncingStateType, Dem_IumprReadinessGroupType, Dem_DTRControlType, Dem_DTCSeverityType, Dem_MonitorStatusType]
      timing event Timer_Dem_MasterMainFunction: start-on-event=Dem_MasterMainFunction, period=0.01
      192 x operation invoked event:
        OpEventPostRunRequested_GetPostRunRequested_DemServices: start-on-event=PostRunRequested, operation=DemServices.GetPostRunRequested
        OpEventGetDTCStatusAvailabilityMask_GetDTCStatusAvailabilityMask_DemServices: start-on-event=GetDTCStatusAvailabilityMask, operation=DemServices.GetDTCStatusAvailabilityMask
        OpEventSetEnableCondition_SetEnableCondition_EnableCond_Being_001: start-on-event=SetEnableCondition, operation=EnableCond_Being_001.SetEnableCondition
        OpEventSetEnableCondition_SetEnableCondition_EnableCond_preheating: start-on-event=SetEnableCondition, operation=EnableCond_preheating.SetEnableCondition
        OpEventSetEnableCondition_SetEnableCondition_EnableCond_HVActive: start-on-event=SetEnableCondition, operation=EnableCond_HVActive.SetEnableCondition
        OpEventSetEnableCondition_SetEnableCondition_EnableCond_performed: start-on-event=SetEnableCondition, operation=EnableCond_performed.SetEnableCondition
        OpEventSetEnableCondition_SetEnableCondition_EnableCond_request: start-on-event=SetEnableCondition, operation=EnableCond_request.SetEnableCondition
        OpEventSetEnableCondition_SetEnableCondition_EnableCond_Heat: start-on-event=SetEnableCondition, operation=EnableCond_Heat.SetEnableCondition
        OpEventSetEnableCondition_SetEnableCondition_EnableCond_Reset_001: start-on-event=SetEnableCondition, operation=EnableCond_Reset_001.SetEnableCondition
        OpEventSetEnableCondition_SetEnableCondition_EnableCond_VCU_: start-on-event=SetEnableCondition, operation=EnableCond_VCU_.SetEnableCondition
        OpEventSetEnableCondition_SetEnableCondition_EnableCond_of: start-on-event=SetEnableCondition, operation=EnableCond_of.SetEnableCondition
        OpEventSetEnableCondition_SetEnableCondition_EnableCond_Note: start-on-event=SetEnableCondition, operation=EnableCond_Note.SetEnableCondition
        OpEventSetEnableCondition_SetEnableCondition_EnableCond_No: start-on-event=SetEnableCondition, operation=EnableCond_No.SetEnableCondition
        OpEventSetEnableCondition_SetEnableCondition_EnableCond_conditions: start-on-event=SetEnableCondition, operation=EnableCond_conditions.SetEnableCondition
        OpEventSetEnableCondition_SetEnableCondition_EnableCond_POD_OBC_VCU_S2_State: start-on-event=SetEnableCondition, operation=EnableCond_POD_OBC_VCU_S2_State.SetEnableCondition
        OpEventSetEnableCondition_SetEnableCondition_EnableCond_or: start-on-event=SetEnableCondition, operation=EnableCond_or.SetEnableCondition
        OpEventSetEnableCondition_SetEnableCondition_EnableCond_detected_001: start-on-event=SetEnableCondition, operation=EnableCond_detected_001.SetEnableCondition
        OpEventSetEnableCondition_SetEnableCondition_EnableCond_Power: start-on-event=SetEnableCondition, operation=EnableCond_Power.SetEnableCondition
        OpEventSetEnableCondition_SetEnableCondition_EnableCond_Enable_001: start-on-event=SetEnableCondition, operation=EnableCond_Enable_001.SetEnableCondition
        OpEventSetEnableCondition_SetEnableCondition_EnableCond_relay: start-on-event=SetEnableCondition, operation=EnableCond_relay.SetEnableCondition
        OpEventSetEnableCondition_SetEnableCondition_EnableCond_v_001: start-on-event=SetEnableCondition, operation=EnableCond_v_001.SetEnableCondition
        OpEventSetEnableCondition_SetEnableCondition_EnableCond_message: start-on-event=SetEnableCondition, operation=EnableCond_message.SetEnableCondition
        OpEventSetEnableCondition_SetEnableCondition_EnableCond_if_001: start-on-event=SetEnableCondition, operation=EnableCond_if_001.SetEnableCondition
        OpEventSetEnableCondition_SetEnableCondition_EnableCond_VCU_ModeRequestDCDC: start-on-event=SetEnableCondition, operation=EnableCond_VCU_ModeRequestDCDC.SetEnableCondition
        OpEventSetEnableCondition_SetEnableCondition_EnableCond_In_001: start-on-event=SetEnableCondition, operation=EnableCond_In_001.SetEnableCondition
        OpEventSetEnableCondition_SetEnableCondition_EnableCond_On: start-on-event=SetEnableCondition, operation=EnableCond_On.SetEnableCondition
        OpEventSetEnableCondition_SetEnableCondition_EnableCond_Conditions_001: start-on-event=SetEnableCondition, operation=EnableCond_Conditions_001.SetEnableCondition
        OpEventSetEnableCondition_SetEnableCondition_EnableCond_Close: start-on-event=SetEnableCondition, operation=EnableCond_Close.SetEnableCondition
        OpEventSetEnableCondition_SetEnableCondition_EnableCond_meet: start-on-event=SetEnableCondition, operation=EnableCond_meet.SetEnableCondition
        OpEventSetEnableCondition_SetEnableCondition_EnableCond_again: start-on-event=SetEnableCondition, operation=EnableCond_again.SetEnableCondition
        OpEventSetEnableCondition_SetEnableCondition_EnableCond_enable: start-on-event=SetEnableCondition, operation=EnableCond_enable.SetEnableCondition
        OpEventSetEnableCondition_SetEnableCondition_EnableCond_start: start-on-event=SetEnableCondition, operation=EnableCond_start.SetEnableCondition
        OpEventSetEnableCondition_SetEnableCondition_EnableCond_fault: start-on-event=SetEnableCondition, operation=EnableCond_fault.SetEnableCondition
        OpEventSetEnableCondition_SetEnableCondition_EnableCond_ms: start-on-event=SetEnableCondition, operation=EnableCond_ms.SetEnableCondition
        OpEventSetEnableCondition_SetEnableCondition_EnableCond_OBC: start-on-event=SetEnableCondition, operation=EnableCond_OBC.SetEnableCondition
        OpEventSetEnableCondition_SetEnableCondition_EnableCond_not: start-on-event=SetEnableCondition, operation=EnableCond_not.SetEnableCondition
        OpEventSetEnableCondition_SetEnableCondition_EnableCond_Open: start-on-event=SetEnableCondition, operation=EnableCond_Open.SetEnableCondition
        OpEventSetEnableCondition_SetEnableCondition_EnableCond_Detected: start-on-event=SetEnableCondition, operation=EnableCond_Detected.SetEnableCondition
        OpEventSetEnableCondition_SetEnableCondition_EnableCond_BHM: start-on-event=SetEnableCondition, operation=EnableCond_BHM.SetEnableCondition
        OpEventSetEnableCondition_SetEnableCondition_EnableCond_Accelerator: start-on-event=SetEnableCondition, operation=EnableCond_Accelerator.SetEnableCondition
        OpEventSetEnableCondition_SetEnableCondition_EnableCond_for: start-on-event=SetEnableCondition, operation=EnableCond_for.SetEnableCondition
        OpEventSetEnableCondition_SetEnableCondition_EnableCond_does: start-on-event=SetEnableCondition, operation=EnableCond_does.SetEnableCondition
        OpEventSetEnableCondition_SetEnableCondition_EnableCond_charging: start-on-event=SetEnableCondition, operation=EnableCond_charging.SetEnableCondition
        OpEventSetEnableCondition_SetEnableCondition_EnableCond_diagnosis: start-on-event=SetEnableCondition, operation=EnableCond_diagnosis.SetEnableCondition
        OpEventSetEnableCondition_SetEnableCondition_EnableCond_Busoff: start-on-event=SetEnableCondition, operation=EnableCond_Busoff.SetEnableCondition
        OpEventSetEnableCondition_SetEnableCondition_EnableCond_last: start-on-event=SetEnableCondition, operation=EnableCond_last.SetEnableCondition
        OpEventSetEnableCondition_SetEnableCondition_EnableCond_be: start-on-event=SetEnableCondition, operation=EnableCond_be.SetEnableCondition
        OpEventSetEnableCondition_SetEnableCondition_EnableCond_recovered: start-on-event=SetEnableCondition, operation=EnableCond_recovered.SetEnableCondition
        OpEventSetEnableCondition_SetEnableCondition_EnableCond_DTC: start-on-event=SetEnableCondition, operation=EnableCond_DTC.SetEnableCondition
        OpEventSetEnableCondition_SetEnableCondition_EnableCond_VCU_OBC_Control_of_em_lock: start-on-event=SetEnableCondition, operation=EnableCond_VCU_OBC_Control_of_em_lock.SetEnableCondition
        OpEventSetEnableCondition_SetEnableCondition_EnableCond_PNC31: start-on-event=SetEnableCondition, operation=EnableCond_PNC31.SetEnableCondition
        OpEventSetEnableCondition_SetEnableCondition_EnableCond_shall: start-on-event=SetEnableCondition, operation=EnableCond_shall.SetEnableCondition
        OpEventSetEnableCondition_SetEnableCondition_EnableCond_all: start-on-event=SetEnableCondition, operation=EnableCond_all.SetEnableCondition
        OpEventSetEnableCondition_SetEnableCondition_EnableCond_pin: start-on-event=SetEnableCondition, operation=EnableCond_pin.SetEnableCondition
        OpEventSetEnableCondition_SetEnableCondition_EnableCond_normal: start-on-event=SetEnableCondition, operation=EnableCond_normal.SetEnableCondition
        OpEventSetEnableCondition_SetEnableCondition_EnableCond_Ohm: start-on-event=SetEnableCondition, operation=EnableCond_Ohm.SetEnableCondition
        OpEventSetEnableCondition_SetEnableCondition_EnableCond_abnormal: start-on-event=SetEnableCondition, operation=EnableCond_abnormal.SetEnableCondition
        OpEventSetEnableCondition_SetEnableCondition_EnableCond_PNC25: start-on-event=SetEnableCondition, operation=EnableCond_PNC25.SetEnableCondition
        OpEventSetEnableCondition_SetEnableCondition_EnableCond_the_001: start-on-event=SetEnableCondition, operation=EnableCond_the_001.SetEnableCondition
        OpEventSetEnableCondition_SetEnableCondition_EnableCond_VCU_Hvstatus_001: start-on-event=SetEnableCondition, operation=EnableCond_VCU_Hvstatus_001.SetEnableCondition
        OpEventSetEnableCondition_SetEnableCondition_EnableCond_DC: start-on-event=SetEnableCondition, operation=EnableCond_DC.SetEnableCondition
        OpEventSetEnableCondition_SetEnableCondition_EnableCond_to: start-on-event=SetEnableCondition, operation=EnableCond_to.SetEnableCondition
        OpEventSetEnableCondition_SetEnableCondition_EnableCond_Lan: start-on-event=SetEnableCondition, operation=EnableCond_Lan.SetEnableCondition
        OpEventSetEnableCondition_SetEnableCondition_EnableCond_requests: start-on-event=SetEnableCondition, operation=EnableCond_requests.SetEnableCondition
        OpEventSetEnableCondition_SetEnableCondition_EnableCond_PNC0: start-on-event=SetEnableCondition, operation=EnableCond_PNC0.SetEnableCondition
        OpEventSetEnableCondition_SetEnableCondition_EnableCond_PNC13: start-on-event=SetEnableCondition, operation=EnableCond_PNC13.SetEnableCondition
        OpEventSetEnableCondition_SetEnableCondition_EnableCond_following: start-on-event=SetEnableCondition, operation=EnableCond_following.SetEnableCondition
        OpEventSetEnableCondition_SetEnableCondition_EnableCond_BMS: start-on-event=SetEnableCondition, operation=EnableCond_BMS.SetEnableCondition
        OpEventSetEnableCondition_SetEnableCondition_EnableCond_PNC15: start-on-event=SetEnableCondition, operation=EnableCond_PNC15.SetEnableCondition
        OpEventSetEnableCondition_SetEnableCondition_EnableCond_PNC14: start-on-event=SetEnableCondition, operation=EnableCond_PNC14.SetEnableCondition
        OpEventSetEnableCondition_SetEnableCondition_EnableCond_PNC16: start-on-event=SetEnableCondition, operation=EnableCond_PNC16.SetEnableCondition
        OpEventSetEnableCondition_SetEnableCondition_EnableCond_PNC18: start-on-event=SetEnableCondition, operation=EnableCond_PNC18.SetEnableCondition
        OpEventSetEnableCondition_SetEnableCondition_EnableCond_All_001: start-on-event=SetEnableCondition, operation=EnableCond_All_001.SetEnableCondition
        OpEventSetEnableCondition_SetEnableCondition_EnableCond_signal: start-on-event=SetEnableCondition, operation=EnableCond_signal.SetEnableCondition
        OpEventSetEnableCondition_SetEnableCondition_EnableCond_T_Delay: start-on-event=SetEnableCondition, operation=EnableCond_T_Delay.SetEnableCondition
        OpEventSetEnableCondition_SetEnableCondition_EnableCond_status: start-on-event=SetEnableCondition, operation=EnableCond_status.SetEnableCondition
        OpEventSetEnableCondition_SetEnableCondition_EnableCond_voltage: start-on-event=SetEnableCondition, operation=EnableCond_voltage.SetEnableCondition
        OpEventSetEnableCondition_SetEnableCondition_EnableCond_Request_001: start-on-event=SetEnableCondition, operation=EnableCond_Request_001.SetEnableCondition
        OpEventSetEnableCondition_SetEnableCondition_EnableCond_BMS_ChargeStatus: start-on-event=SetEnableCondition, operation=EnableCond_BMS_ChargeStatus.SetEnableCondition
        OpEventSetEnableCondition_SetEnableCondition_EnableCond_AC: start-on-event=SetEnableCondition, operation=EnableCond_AC.SetEnableCondition
        OpEventSetEnableCondition_SetEnableCondition_EnableCond_accelerator_001: start-on-event=SetEnableCondition, operation=EnableCond_accelerator_001.SetEnableCondition
        OpEventSetEnableCondition_SetEnableCondition_EnableCond_after: start-on-event=SetEnableCondition, operation=EnableCond_after.SetEnableCondition
        OpEventSetEnableCondition_SetEnableCondition_EnableCond_KL15E_001: start-on-event=SetEnableCondition, operation=EnableCond_KL15E_001.SetEnableCondition
        OpEventSetEnableCondition_SetEnableCondition_EnableCond_PNC04: start-on-event=SetEnableCondition, operation=EnableCond_PNC04.SetEnableCondition
        OpEventSetEnableCondition_SetEnableCondition_EnableCond_PNC03: start-on-event=SetEnableCondition, operation=EnableCond_PNC03.SetEnableCondition
        OpEventSetEnableCondition_SetEnableCondition_EnableCond_VCU: start-on-event=SetEnableCondition, operation=EnableCond_VCU.SetEnableCondition
        OpEventSetEnableCondition_SetEnableCondition_EnableCond_positive: start-on-event=SetEnableCondition, operation=EnableCond_positive.SetEnableCondition
        OpEventSetEnableCondition_SetEnableCondition_EnableCond_S2: start-on-event=SetEnableCondition, operation=EnableCond_S2.SetEnableCondition
        OpEventSetEnableCondition_SetEnableCondition_EnableCond_VCU_RequestedModeTCU: start-on-event=SetEnableCondition, operation=EnableCond_VCU_RequestedModeTCU.SetEnableCondition
        OpEventSetEnableCondition_SetEnableCondition_EnableCond_Control: start-on-event=SetEnableCondition, operation=EnableCond_Control.SetEnableCondition
        OpEventSetEnableCondition_SetEnableCondition_EnableCond_being: start-on-event=SetEnableCondition, operation=EnableCond_being.SetEnableCondition
        OpEventSetEnableCondition_SetEnableCondition_EnableCond_POD_OBC_CCStatus: start-on-event=SetEnableCondition, operation=EnableCond_POD_OBC_CCStatus.SetEnableCondition
        OpEventSetEnableCondition_SetEnableCondition_EnableCond_switch: start-on-event=SetEnableCondition, operation=EnableCond_switch.SetEnableCondition
        OpEventSetEnableCondition_SetEnableCondition_EnableCond_VCU_EnableOBC: start-on-event=SetEnableCondition, operation=EnableCond_VCU_EnableOBC.SetEnableCondition
        OpEventSetEnableCondition_SetEnableCondition_EnableCond_VCU_RequestedModeBMS: start-on-event=SetEnableCondition, operation=EnableCond_VCU_RequestedModeBMS.SetEnableCondition
        OpEventSetEnableCondition_SetEnableCondition_EnableCond_TrqCtrl: start-on-event=SetEnableCondition, operation=EnableCond_TrqCtrl.SetEnableCondition
        OpEventSetEnableCondition_SetEnableCondition_EnableCond_POD: start-on-event=SetEnableCondition, operation=EnableCond_POD.SetEnableCondition
        OpEventSetEnableCondition_SetEnableCondition_EnableCond_function: start-on-event=SetEnableCondition, operation=EnableCond_function.SetEnableCondition
        OpEventSetEnableCondition_SetEnableCondition_EnableCond_KL15eWakeUp: start-on-event=SetEnableCondition, operation=EnableCond_KL15eWakeUp.SetEnableCondition
        OpEventSetEnableCondition_SetEnableCondition_EnableCond_service: start-on-event=SetEnableCondition, operation=EnableCond_service.SetEnableCondition
        OpEventSetEnableCondition_SetEnableCondition_EnableCond_pin1: start-on-event=SetEnableCondition, operation=EnableCond_pin1.SetEnableCondition
        OpEventSetEnableCondition_SetEnableCondition_EnableCond_pin2: start-on-event=SetEnableCondition, operation=EnableCond_pin2.SetEnableCondition
        OpEventSetEnableCondition_SetEnableCondition_EnableCond_Init: start-on-event=SetEnableCondition, operation=EnableCond_Init.SetEnableCondition
        OpEventSetEnableCondition_SetEnableCondition_EnableCond_close_001: start-on-event=SetEnableCondition, operation=EnableCond_close_001.SetEnableCondition
        OpEventSetEnableCondition_SetEnableCondition_EnableCond_completed: start-on-event=SetEnableCondition, operation=EnableCond_completed.SetEnableCondition
        OpEventSetEnableCondition_SetEnableCondition_EnableCond_closed: start-on-event=SetEnableCondition, operation=EnableCond_closed.SetEnableCondition
        OpEventSetEnableCondition_SetEnableCondition_EnableCond_disconnect: start-on-event=SetEnableCondition, operation=EnableCond_disconnect.SetEnableCondition
        OpEventSetEnableCondition_SetEnableCondition_EnableCond_lock: start-on-event=SetEnableCondition, operation=EnableCond_lock.SetEnableCondition
        OpEventSetEnableCondition_SetEnableCondition_EnableCond_VCU_ChargeStatus: start-on-event=SetEnableCondition, operation=EnableCond_VCU_ChargeStatus.SetEnableCondition
        OpEventSetEnableCondition_SetEnableCondition_EnableCond_guns: start-on-event=SetEnableCondition, operation=EnableCond_guns.SetEnableCondition
        OpEventSetEnableCondition_SetEnableCondition_EnableCond_VCU_Enable_DC_Relay: start-on-event=SetEnableCondition, operation=EnableCond_VCU_Enable_DC_Relay.SetEnableCondition
        OpEventSetEnableCondition_SetEnableCondition_EnableCond_BRM: start-on-event=SetEnableCondition, operation=EnableCond_BRM.SetEnableCondition
        OpEventSetEnableCondition_SetEnableCondition_EnableCond_ON_001: start-on-event=SetEnableCondition, operation=EnableCond_ON_001.SetEnableCondition
        OpEventSetEnableCondition_SetEnableCondition_EnableCond_electronic: start-on-event=SetEnableCondition, operation=EnableCond_electronic.SetEnableCondition
        OpEventSetEnableCondition_SetEnableCondition_EnableCond_VCU_MCURequestedState: start-on-event=SetEnableCondition, operation=EnableCond_VCU_MCURequestedState.SetEnableCondition
        OpEventSetEnableCondition_SetEnableCondition_EnableCond_do: start-on-event=SetEnableCondition, operation=EnableCond_do.SetEnableCondition
        OpEventSetEnableCondition_SetEnableCondition_EnableCond_Charging_001: start-on-event=SetEnableCondition, operation=EnableCond_Charging_001.SetEnableCondition
        OpEventSetEnableCondition_SetEnableCondition_EnableCond_negative: start-on-event=SetEnableCondition, operation=EnableCond_negative.SetEnableCondition
        OpEventSetEnableCondition_SetEnableCondition_EnableCond_any: start-on-event=SetEnableCondition, operation=EnableCond_any.SetEnableCondition
        OpEventSetEnableCondition_SetEnableCondition_EnableCond_recovers: start-on-event=SetEnableCondition, operation=EnableCond_recovers.SetEnableCondition
        OpEventSetEnableCondition_SetEnableCondition_EnableCond_condition: start-on-event=SetEnableCondition, operation=EnableCond_condition.SetEnableCondition
        OpEventSetEnableCondition_SetEnableCondition_EnableCond_Confirmed: start-on-event=SetEnableCondition, operation=EnableCond_Confirmed.SetEnableCondition
        OpEventSetEnableCondition_SetEnableCondition_EnableCond_When: start-on-event=SetEnableCondition, operation=EnableCond_When.SetEnableCondition
        OpEventSetEnableCondition_SetEnableCondition_EnableCond_up: start-on-event=SetEnableCondition, operation=EnableCond_up.SetEnableCondition
        OpEventSetEnableCondition_SetEnableCondition_EnableCond_met: start-on-event=SetEnableCondition, operation=EnableCond_met.SetEnableCondition
        OpEventSetEnableCondition_SetEnableCondition_EnableCond_and: start-on-event=SetEnableCondition, operation=EnableCond_and.SetEnableCondition
        OpEventSetEnableCondition_SetEnableCondition_EnableCond_timing: start-on-event=SetEnableCondition, operation=EnableCond_timing.SetEnableCondition
        OpEventSetEnableCondition_SetEnableCondition_EnableCond_Disable: start-on-event=SetEnableCondition, operation=EnableCond_Disable.SetEnableCondition
        OpEventSetEnableCondition_SetEnableCondition_EnableCond_x0: start-on-event=SetEnableCondition, operation=EnableCond_x0.SetEnableCondition
        OpEventSetEnableCondition_SetEnableCondition_EnableCond_x1: start-on-event=SetEnableCondition, operation=EnableCond_x1.SetEnableCondition
        OpEventSetEnableCondition_SetEnableCondition_EnableCond_reset: start-on-event=SetEnableCondition, operation=EnableCond_reset.SetEnableCondition
        OpEventSetEnableCondition_SetEnableCondition_EnableCond_ModeRequestDCDC: start-on-event=SetEnableCondition, operation=EnableCond_ModeRequestDCDC.SetEnableCondition
        OpEventSetEnableCondition_SetEnableCondition_EnableCond_BMS_status: start-on-event=SetEnableCondition, operation=EnableCond_BMS_status.SetEnableCondition
        OpEventSetEnableCondition_SetEnableCondition_EnableCond_active: start-on-event=SetEnableCondition, operation=EnableCond_active.SetEnableCondition
        OpEventSetEnableCondition_SetEnableCondition_EnableCond_requirements: start-on-event=SetEnableCondition, operation=EnableCond_requirements.SetEnableCondition
        OpEventSetEnableCondition_SetEnableCondition_EnableCond_pedal: start-on-event=SetEnableCondition, operation=EnableCond_pedal.SetEnableCondition
        OpEventSetEnableCondition_SetEnableCondition_EnableCond_x4: start-on-event=SetEnableCondition, operation=EnableCond_x4.SetEnableCondition
        OpEventSetEnableCondition_SetEnableCondition_EnableCond_Standby: start-on-event=SetEnableCondition, operation=EnableCond_Standby.SetEnableCondition
        OpEventSetEnableCondition_SetEnableCondition_EnableCond_x5: start-on-event=SetEnableCondition, operation=EnableCond_x5.SetEnableCondition
        OpEventSetEnableCondition_SetEnableCondition_EnableCond_x2: start-on-event=SetEnableCondition, operation=EnableCond_x2.SetEnableCondition
        OpEventSetEnableCondition_SetEnableCondition_EnableCond_x3: start-on-event=SetEnableCondition, operation=EnableCond_x3.SetEnableCondition
        OpEventSetEnableCondition_SetEnableCondition_EnableCond_timer: start-on-event=SetEnableCondition, operation=EnableCond_timer.SetEnableCondition
        OpEventSetEnableCondition_SetEnableCondition_EnableCond_criteria: start-on-event=SetEnableCondition, operation=EnableCond_criteria.SetEnableCondition
        OpEventSetEnableCondition_SetEnableCondition_EnableCond_times: start-on-event=SetEnableCondition, operation=EnableCond_times.SetEnableCondition
        OpEventSetEnableCondition_SetEnableCondition_EnableCond_Non: start-on-event=SetEnableCondition, operation=EnableCond_Non.SetEnableCondition
        OpEventSetEnableCondition_SetEnableCondition_EnableCond_confirmation: start-on-event=SetEnableCondition, operation=EnableCond_confirmation.SetEnableCondition
        OpEventSetEnableCondition_SetEnableCondition_EnableCond_trigger: start-on-event=SetEnableCondition, operation=EnableCond_trigger.SetEnableCondition
        OpEventSetEnableCondition_SetEnableCondition_EnableCond_simultaneously: start-on-event=SetEnableCondition, operation=EnableCond_simultaneously.SetEnableCondition
        OpEventSetEnableCondition_SetEnableCondition_EnableCond_InActive: start-on-event=SetEnableCondition, operation=EnableCond_InActive.SetEnableCondition
        OpEventSetEnableCondition_SetEnableCondition_EnableCond_battery: start-on-event=SetEnableCondition, operation=EnableCond_battery.SetEnableCondition
        OpEventSetEnableCondition_SetEnableCondition_EnableCond_main: start-on-event=SetEnableCondition, operation=EnableCond_main.SetEnableCondition
        OpEventSetEnableCondition_SetEnableCondition_EnableCond_from: start-on-event=SetEnableCondition, operation=EnableCond_from.SetEnableCondition
        OpEventSetEnableCondition_SetEnableCondition_EnableCond_Plug: start-on-event=SetEnableCondition, operation=EnableCond_Plug.SetEnableCondition
        OpEventSetEnableCondition_SetEnableCondition_EnableCond_waked: start-on-event=SetEnableCondition, operation=EnableCond_waked.SetEnableCondition
        OpEventSetEnableCondition_SetEnableCondition_EnableCond_charge: start-on-event=SetEnableCondition, operation=EnableCond_charge.SetEnableCondition
        OpEventSetEnableCondition_SetEnableCondition_EnableCond_process: start-on-event=SetEnableCondition, operation=EnableCond_process.SetEnableCondition
        OpEventSetEnableCondition_SetEnableCondition_EnableCond_Chargestatus: start-on-event=SetEnableCondition, operation=EnableCond_Chargestatus.SetEnableCondition
        OpEventSetEnableCondition_SetEnableCondition_EnableCond_during: start-on-event=SetEnableCondition, operation=EnableCond_during.SetEnableCondition
        OpEventSetEnableCondition_SetEnableCondition_EnableCond_KL15e: start-on-event=SetEnableCondition, operation=EnableCond_KL15e.SetEnableCondition
        OpEventSetEnableCondition_SetEnableCondition_EnableCond_only: start-on-event=SetEnableCondition, operation=EnableCond_only.SetEnableCondition
        OpEventSetEnableCondition_SetEnableCondition_EnableCond_MCU_VCUWorkMode: start-on-event=SetEnableCondition, operation=EnableCond_MCU_VCUWorkMode.SetEnableCondition
        OpEventSetEnableCondition_SetEnableCondition_EnableCond_High: start-on-event=SetEnableCondition, operation=EnableCond_High.SetEnableCondition
        OpEventSetEnableCondition_SetEnableCondition_EnableCond_Torque: start-on-event=SetEnableCondition, operation=EnableCond_Torque.SetEnableCondition
        OpEventSetEnableCondition_SetEnableCondition_EnableCond_V: start-on-event=SetEnableCondition, operation=EnableCond_V.SetEnableCondition
        OpEventSetEnableCondition_SetEnableCondition_EnableCond_serviceNote: start-on-event=SetEnableCondition, operation=EnableCond_serviceNote.SetEnableCondition
        OpEventSetEnableCondition_SetEnableCondition_EnableCond_VCU_BMS_Control_of_NegRelay: start-on-event=SetEnableCondition, operation=EnableCond_VCU_BMS_Control_of_NegRelay.SetEnableCondition
        OpEventSetEnableCondition_SetEnableCondition_EnableCond_sends: start-on-event=SetEnableCondition, operation=EnableCond_sends.SetEnableCondition
        OpEventSetEnableCondition_SetEnableCondition_EnableCond_opening: start-on-event=SetEnableCondition, operation=EnableCond_opening.SetEnableCondition
        OpEventSetEnableCondition_SetEnableCondition_EnableCond_LAN_001: start-on-event=SetEnableCondition, operation=EnableCond_LAN_001.SetEnableCondition
        OpEventSetEnableCondition_SetEnableCondition_EnableCond_in: start-on-event=SetEnableCondition, operation=EnableCond_in.SetEnableCondition
        OpEventSetEnableCondition_SetEnableCondition_EnableCond_Ready: start-on-event=SetEnableCondition, operation=EnableCond_Ready.SetEnableCondition
        OpEventSetEnableCondition_SetEnableCondition_EnableCond_Buck: start-on-event=SetEnableCondition, operation=EnableCond_Buck.SetEnableCondition
        OpEventSetEnableCondition_SetEnableCondition_EnableCond_are: start-on-event=SetEnableCondition, operation=EnableCond_are.SetEnableCondition
        OpEventSetEnableCondition_SetEnableCondition_EnableCond_is: start-on-event=SetEnableCondition, operation=EnableCond_is.SetEnableCondition
        OpEventSetEnableCondition_SetEnableCondition_EnableCond_The: start-on-event=SetEnableCondition, operation=EnableCond_The.SetEnableCondition
        OpEventSetEnableCondition_SetEnableCondition_EnableCond_s: start-on-event=SetEnableCondition, operation=EnableCond_s.SetEnableCondition
        OpEventSetEnableCondition_SetEnableCondition_EnableCond_If: start-on-event=SetEnableCondition, operation=EnableCond_If.SetEnableCondition
        OpEventSetEnableCondition_SetEnableCondition_EnableCond_restored: start-on-event=SetEnableCondition, operation=EnableCond_restored.SetEnableCondition
        OpEventGetIndicatorStatus_GetIndicatorStatus_IndStatus_WarningIndicator: start-on-event=GetIndicatorStatus, operation=IndStatus_WarningIndicator.GetIndicatorStatus
        OpEventGetEventUdsStatus_GetEventUdsStatus_GeneralEvtInfo: start-on-event=DemMaster_0InternalBehavior/GetEventUdsStatus, operation=GeneralEvtInfo.GetEventUdsStatus
        OpEventGetEventStatus_GetEventStatus_GeneralEvtInfo: start-on-event=DemMaster_0InternalBehavior/GetEventStatus, operation=GeneralEvtInfo.GetEventStatus
        OpEventGetEventFailed_GetEventFailed_GeneralEvtInfo: start-on-event=DemMaster_0InternalBehavior/GetEventFailed, operation=GeneralEvtInfo.GetEventFailed
        OpEventGetEventTested_GetEventTested_GeneralEvtInfo: start-on-event=DemMaster_0InternalBehavior/GetEventTested, operation=GeneralEvtInfo.GetEventTested
        OpEventGetDTCOfEvent_GetDTCOfEvent_GeneralEvtInfo: start-on-event=DemMaster_0InternalBehavior/GetDTCOfEvent, operation=GeneralEvtInfo.GetDTCOfEvent
        OpEventGetFaultDetectionCounter_GetFaultDetectionCounter_GeneralEvtInfo: start-on-event=DemMaster_0InternalBehavior/GetFaultDetectionCounter, operation=GeneralEvtInfo.GetFaultDetectionCounter
        OpEventGetEventFreezeFrameDataEx_GetEventFreezeFrameDataEx_GeneralEvtInfo: start-on-event=DemMaster_0InternalBehavior/GetEventFreezeFrameDataEx, operation=GeneralEvtInfo.GetEventFreezeFrameDataEx
        OpEventGetEventExtendedDataRecordEx_GetEventExtendedDataRecordEx_GeneralEvtInfo: start-on-event=DemMaster_0InternalBehavior/GetEventExtendedDataRecordEx, operation=GeneralEvtInfo.GetEventExtendedDataRecordEx
        OpEventGetEventEnableCondition_GetEventEnableCondition_GeneralEvtInfo: start-on-event=DemMaster_0InternalBehavior/GetEventEnableCondition, operation=GeneralEvtInfo.GetEventEnableCondition
        OpEventGetDebouncingOfEvent_GetDebouncingOfEvent_GeneralEvtInfo: start-on-event=DemMaster_0InternalBehavior/GetDebouncingOfEvent, operation=GeneralEvtInfo.GetDebouncingOfEvent
        OpEventGetMonitorStatus_GetMonitorStatus_GeneralEvtInfo: start-on-event=DemMaster_0InternalBehavior/GetMonitorStatus, operation=GeneralEvtInfo.GetMonitorStatus
        OpEventGetOperationCycleState_GetOperationCycleState_OpCycle_PowerCycle: start-on-event=GetOperationCycleState, operation=OpCycle_PowerCycle.GetOperationCycleState
        OpEventSetOperationCycleState_SetOperationCycleState_OpCycle_PowerCycle: start-on-event=SetOperationCycleState, operation=OpCycle_PowerCycle.SetOperationCycleState
      port-api-options:
        enable-take-address=true, indirect-api=false, port=DemServices
        {enable-take-address=true, indirect-api=false, port-defined-argument-value{value=9, value-type=uint8}, port=EnableCond_Being_001}
        {enable-take-address=true, indirect-api=false, port-defined-argument-value{value=141, value-type=uint8}, port=EnableCond_preheating}
        {enable-take-address=true, indirect-api=false, port-defined-argument-value{value=23, value-type=uint8}, port=EnableCond_HVActive}
        {enable-take-address=true, indirect-api=false, port-defined-argument-value{value=136, value-type=uint8}, port=EnableCond_performed}
        {enable-take-address=true, indirect-api=false, port-defined-argument-value{value=146, value-type=uint8}, port=EnableCond_request}
        {enable-take-address=true, indirect-api=false, port-defined-argument-value{value=24, value-type=uint8}, port=EnableCond_Heat}
        {enable-take-address=true, indirect-api=false, port-defined-argument-value{value=62, value-type=uint8}, port=EnableCond_Reset_001}
        {enable-take-address=true, indirect-api=false, port-defined-argument-value{value=71, value-type=uint8}, port=EnableCond_VCU_}
        {enable-take-address=true, indirect-api=false, port-defined-argument-value{value=131, value-type=uint8}, port=EnableCond_of}
        {enable-take-address=true, indirect-api=false, port-defined-argument-value{value=39, value-type=uint8}, port=EnableCond_Note}
        {enable-take-address=true, indirect-api=false, port-defined-argument-value{value=37, value-type=uint8}, port=EnableCond_No}
        {enable-take-address=true, indirect-api=false, port-defined-argument-value{value=101, value-type=uint8}, port=EnableCond_conditions}
        {enable-take-address=true, indirect-api=false, port-defined-argument-value{value=57, value-type=uint8}, port=EnableCond_POD_OBC_VCU_S2_State}
        {enable-take-address=true, indirect-api=false, port-defined-argument-value{value=134, value-type=uint8}, port=EnableCond_or}
        {enable-take-address=true, indirect-api=false, port-defined-argument-value{value=104, value-type=uint8}, port=EnableCond_detected_001}
        {enable-take-address=true, indirect-api=false, port-defined-argument-value{value=59, value-type=uint8}, port=EnableCond_Power}
        {enable-take-address=true, indirect-api=false, port-defined-argument-value{value=22, value-type=uint8}, port=EnableCond_Enable_001}
        {enable-take-address=true, indirect-api=false, port-defined-argument-value{value=145, value-type=uint8}, port=EnableCond_relay}
        {enable-take-address=true, indirect-api=false, port-defined-argument-value{value=168, value-type=uint8}, port=EnableCond_v_001}
        {enable-take-address=true, indirect-api=false, port-defined-argument-value{value=125, value-type=uint8}, port=EnableCond_message}
        {enable-take-address=true, indirect-api=false, port-defined-argument-value{value=118, value-type=uint8}, port=EnableCond_if_001}
        {enable-take-address=true, indirect-api=false, port-defined-argument-value{value=78, value-type=uint8}, port=EnableCond_VCU_ModeRequestDCDC}
        {enable-take-address=true, indirect-api=false, port-defined-argument-value{value=28, value-type=uint8}, port=EnableCond_In_001}
        {enable-take-address=true, indirect-api=false, port-defined-argument-value{value=43, value-type=uint8}, port=EnableCond_On}
        {enable-take-address=true, indirect-api=false, port-defined-argument-value{value=15, value-type=uint8}, port=EnableCond_Conditions_001}
        {enable-take-address=true, indirect-api=false, port-defined-argument-value{value=14, value-type=uint8}, port=EnableCond_Close}
        {enable-take-address=true, indirect-api=false, port-defined-argument-value{value=124, value-type=uint8}, port=EnableCond_meet}
        {enable-take-address=true, indirect-api=false, port-defined-argument-value{value=87, value-type=uint8}, port=EnableCond_again}
        {enable-take-address=true, indirect-api=false, port-defined-argument-value{value=111, value-type=uint8}, port=EnableCond_enable}
        {enable-take-address=true, indirect-api=false, port-defined-argument-value{value=158, value-type=uint8}, port=EnableCond_start}
        {enable-take-address=true, indirect-api=false, port-defined-argument-value{value=112, value-type=uint8}, port=EnableCond_fault}
        {enable-take-address=true, indirect-api=false, port-defined-argument-value{value=127, value-type=uint8}, port=EnableCond_ms}
        {enable-take-address=true, indirect-api=false, port-defined-argument-value{value=40, value-type=uint8}, port=EnableCond_OBC}
        {enable-take-address=true, indirect-api=false, port-defined-argument-value{value=130, value-type=uint8}, port=EnableCond_not}
        {enable-take-address=true, indirect-api=false, port-defined-argument-value{value=44, value-type=uint8}, port=EnableCond_Open}
        {enable-take-address=true, indirect-api=false, port-defined-argument-value{value=20, value-type=uint8}, port=EnableCond_Detected}
        {enable-take-address=true, indirect-api=false, port-defined-argument-value{value=4, value-type=uint8}, port=EnableCond_BHM}
        {enable-take-address=true, indirect-api=false, port-defined-argument-value{value=2, value-type=uint8}, port=EnableCond_Accelerator}
        {enable-take-address=true, indirect-api=false, port-defined-argument-value{value=114, value-type=uint8}, port=EnableCond_for}
        {enable-take-address=true, indirect-api=false, port-defined-argument-value{value=108, value-type=uint8}, port=EnableCond_does}
        {enable-take-address=true, indirect-api=false, port-defined-argument-value{value=96, value-type=uint8}, port=EnableCond_charging}
        {enable-take-address=true, indirect-api=false, port-defined-argument-value{value=105, value-type=uint8}, port=EnableCond_diagnosis}
        {enable-take-address=true, indirect-api=false, port-defined-argument-value{value=11, value-type=uint8}, port=EnableCond_Busoff}
        {enable-take-address=true, indirect-api=false, port-defined-argument-value{value=121, value-type=uint8}, port=EnableCond_last}
        {enable-take-address=true, indirect-api=false, port-defined-argument-value{value=93, value-type=uint8}, port=EnableCond_be}
        {enable-take-address=true, indirect-api=false, port-defined-argument-value{value=143, value-type=uint8}, port=EnableCond_recovered}
        {enable-take-address=true, indirect-api=false, port-defined-argument-value{value=19, value-type=uint8}, port=EnableCond_DTC}
        {enable-take-address=true, indirect-api=false, port-defined-argument-value{value=79, value-type=uint8}, port=EnableCond_VCU_OBC_Control_of_em_lock}
        {enable-take-address=true, indirect-api=false, port-defined-argument-value{value=54, value-type=uint8}, port=EnableCond_PNC31}
        {enable-take-address=true, indirect-api=false, port-defined-argument-value{value=155, value-type=uint8}, port=EnableCond_shall}
        {enable-take-address=true, indirect-api=false, port-defined-argument-value{value=88, value-type=uint8}, port=EnableCond_all}
        {enable-take-address=true, indirect-api=false, port-defined-argument-value{value=137, value-type=uint8}, port=EnableCond_pin}
        {enable-take-address=true, indirect-api=false, port-defined-argument-value{value=129, value-type=uint8}, port=EnableCond_normal}
        {enable-take-address=true, indirect-api=false, port-defined-argument-value{value=42, value-type=uint8}, port=EnableCond_Ohm}
        {enable-take-address=true, indirect-api=false, port-defined-argument-value{value=83, value-type=uint8}, port=EnableCond_abnormal}
        {enable-take-address=true, indirect-api=false, port-defined-argument-value{value=53, value-type=uint8}, port=EnableCond_PNC25}
        {enable-take-address=true, indirect-api=false, port-defined-argument-value{value=161, value-type=uint8}, port=EnableCond_the_001}
        {enable-take-address=true, indirect-api=false, port-defined-argument-value{value=76, value-type=uint8}, port=EnableCond_VCU_Hvstatus_001}
        {enable-take-address=true, indirect-api=false, port-defined-argument-value{value=18, value-type=uint8}, port=EnableCond_DC}
        {enable-take-address=true, indirect-api=false, port-defined-argument-value{value=165, value-type=uint8}, port=EnableCond_to}
        {enable-take-address=true, indirect-api=false, port-defined-argument-value{value=34, value-type=uint8}, port=EnableCond_Lan}
        {enable-take-address=true, indirect-api=false, port-defined-argument-value{value=147, value-type=uint8}, port=EnableCond_requests}
        {enable-take-address=true, indirect-api=false, port-defined-argument-value{value=45, value-type=uint8}, port=EnableCond_PNC0}
        {enable-take-address=true, indirect-api=false, port-defined-argument-value{value=48, value-type=uint8}, port=EnableCond_PNC13}
        {enable-take-address=true, indirect-api=false, port-defined-argument-value{value=113, value-type=uint8}, port=EnableCond_following}
        {enable-take-address=true, indirect-api=false, port-defined-argument-value{value=5, value-type=uint8}, port=EnableCond_BMS}
        {enable-take-address=true, indirect-api=false, port-defined-argument-value{value=50, value-type=uint8}, port=EnableCond_PNC15}
        {enable-take-address=true, indirect-api=false, port-defined-argument-value{value=49, value-type=uint8}, port=EnableCond_PNC14}
        {enable-take-address=true, indirect-api=false, port-defined-argument-value{value=51, value-type=uint8}, port=EnableCond_PNC16}
        {enable-take-address=true, indirect-api=false, port-defined-argument-value{value=52, value-type=uint8}, port=EnableCond_PNC18}
        {enable-take-address=true, indirect-api=false, port-defined-argument-value{value=3, value-type=uint8}, port=EnableCond_All_001}
        {enable-take-address=true, indirect-api=false, port-defined-argument-value{value=156, value-type=uint8}, port=EnableCond_signal}
        {enable-take-address=true, indirect-api=false, port-defined-argument-value{value=65, value-type=uint8}, port=EnableCond_T_Delay}
        {enable-take-address=true, indirect-api=false, port-defined-argument-value{value=159, value-type=uint8}, port=EnableCond_status}
        {enable-take-address=true, indirect-api=false, port-defined-argument-value{value=169, value-type=uint8}, port=EnableCond_voltage}
        {enable-take-address=true, indirect-api=false, port-defined-argument-value{value=61, value-type=uint8}, port=EnableCond_Request_001}
        {enable-take-address=true, indirect-api=false, port-defined-argument-value{value=6, value-type=uint8}, port=EnableCond_BMS_ChargeStatus}
        {enable-take-address=true, indirect-api=false, port-defined-argument-value{value=1, value-type=uint8}, port=EnableCond_AC}
        {enable-take-address=true, indirect-api=false, port-defined-argument-value{value=84, value-type=uint8}, port=EnableCond_accelerator_001}
        {enable-take-address=true, indirect-api=false, port-defined-argument-value{value=86, value-type=uint8}, port=EnableCond_after}
        {enable-take-address=true, indirect-api=false, port-defined-argument-value{value=30, value-type=uint8}, port=EnableCond_KL15E_001}
        {enable-take-address=true, indirect-api=false, port-defined-argument-value{value=47, value-type=uint8}, port=EnableCond_PNC04}
        {enable-take-address=true, indirect-api=false, port-defined-argument-value{value=46, value-type=uint8}, port=EnableCond_PNC03}
        {enable-take-address=true, indirect-api=false, port-defined-argument-value{value=70, value-type=uint8}, port=EnableCond_VCU}
        {enable-take-address=true, indirect-api=false, port-defined-argument-value{value=140, value-type=uint8}, port=EnableCond_positive}
        {enable-take-address=true, indirect-api=false, port-defined-argument-value{value=63, value-type=uint8}, port=EnableCond_S2}
        {enable-take-address=true, indirect-api=false, port-defined-argument-value{value=81, value-type=uint8}, port=EnableCond_VCU_RequestedModeTCU}
        {enable-take-address=true, indirect-api=false, port-defined-argument-value{value=17, value-type=uint8}, port=EnableCond_Control}
        {enable-take-address=true, indirect-api=false, port-defined-argument-value{value=94, value-type=uint8}, port=EnableCond_being}
        {enable-take-address=true, indirect-api=false, port-defined-argument-value{value=56, value-type=uint8}, port=EnableCond_POD_OBC_CCStatus}
        {enable-take-address=true, indirect-api=false, port-defined-argument-value{value=160, value-type=uint8}, port=EnableCond_switch}
        {enable-take-address=true, indirect-api=false, port-defined-argument-value{value=74, value-type=uint8}, port=EnableCond_VCU_EnableOBC}
        {enable-take-address=true, indirect-api=false, port-defined-argument-value{value=80, value-type=uint8}, port=EnableCond_VCU_RequestedModeBMS}
        {enable-take-address=true, indirect-api=false, port-defined-argument-value{value=68, value-type=uint8}, port=EnableCond_TrqCtrl}
        {enable-take-address=true, indirect-api=false, port-defined-argument-value{value=55, value-type=uint8}, port=EnableCond_POD}
        {enable-take-address=true, indirect-api=false, port-defined-argument-value{value=116, value-type=uint8}, port=EnableCond_function}
        {enable-take-address=true, indirect-api=false, port-defined-argument-value{value=32, value-type=uint8}, port=EnableCond_KL15eWakeUp}
        {enable-take-address=true, indirect-api=false, port-defined-argument-value{value=153, value-type=uint8}, port=EnableCond_service}
        {enable-take-address=true, indirect-api=false, port-defined-argument-value{value=138, value-type=uint8}, port=EnableCond_pin1}
        {enable-take-address=true, indirect-api=false, port-defined-argument-value{value=139, value-type=uint8}, port=EnableCond_pin2}
        {enable-take-address=true, indirect-api=false, port-defined-argument-value{value=29, value-type=uint8}, port=EnableCond_Init}
        {enable-take-address=true, indirect-api=false, port-defined-argument-value{value=97, value-type=uint8}, port=EnableCond_close_001}
        {enable-take-address=true, indirect-api=false, port-defined-argument-value{value=99, value-type=uint8}, port=EnableCond_completed}
        {enable-take-address=true, indirect-api=false, port-defined-argument-value{value=98, value-type=uint8}, port=EnableCond_closed}
        {enable-take-address=true, indirect-api=false, port-defined-argument-value{value=106, value-type=uint8}, port=EnableCond_disconnect}
        {enable-take-address=true, indirect-api=false, port-defined-argument-value{value=122, value-type=uint8}, port=EnableCond_lock}
        {enable-take-address=true, indirect-api=false, port-defined-argument-value{value=73, value-type=uint8}, port=EnableCond_VCU_ChargeStatus}
        {enable-take-address=true, indirect-api=false, port-defined-argument-value{value=117, value-type=uint8}, port=EnableCond_guns}
        {enable-take-address=true, indirect-api=false, port-defined-argument-value{value=75, value-type=uint8}, port=EnableCond_VCU_Enable_DC_Relay}
        {enable-take-address=true, indirect-api=false, port-defined-argument-value{value=8, value-type=uint8}, port=EnableCond_BRM}
        {enable-take-address=true, indirect-api=false, port-defined-argument-value{value=41, value-type=uint8}, port=EnableCond_ON_001}
        {enable-take-address=true, indirect-api=false, port-defined-argument-value{value=110, value-type=uint8}, port=EnableCond_electronic}
        {enable-take-address=true, indirect-api=false, port-defined-argument-value{value=77, value-type=uint8}, port=EnableCond_VCU_MCURequestedState}
        {enable-take-address=true, indirect-api=false, port-defined-argument-value{value=107, value-type=uint8}, port=EnableCond_do}
        {enable-take-address=true, indirect-api=false, port-defined-argument-value{value=13, value-type=uint8}, port=EnableCond_Charging_001}
        {enable-take-address=true, indirect-api=false, port-defined-argument-value{value=128, value-type=uint8}, port=EnableCond_negative}
        {enable-take-address=true, indirect-api=false, port-defined-argument-value{value=90, value-type=uint8}, port=EnableCond_any}
        {enable-take-address=true, indirect-api=false, port-defined-argument-value{value=144, value-type=uint8}, port=EnableCond_recovers}
        {enable-take-address=true, indirect-api=false, port-defined-argument-value{value=100, value-type=uint8}, port=EnableCond_condition}
        {enable-take-address=true, indirect-api=false, port-defined-argument-value{value=16, value-type=uint8}, port=EnableCond_Confirmed}
        {enable-take-address=true, indirect-api=false, port-defined-argument-value{value=82, value-type=uint8}, port=EnableCond_When}
        {enable-take-address=true, indirect-api=false, port-defined-argument-value{value=167, value-type=uint8}, port=EnableCond_up}
        {enable-take-address=true, indirect-api=false, port-defined-argument-value{value=126, value-type=uint8}, port=EnableCond_met}
        {enable-take-address=true, indirect-api=false, port-defined-argument-value{value=89, value-type=uint8}, port=EnableCond_and}
        {enable-take-address=true, indirect-api=false, port-defined-argument-value{value=164, value-type=uint8}, port=EnableCond_timing}
        {enable-take-address=true, indirect-api=false, port-defined-argument-value{value=21, value-type=uint8}, port=EnableCond_Disable}
        {enable-take-address=true, indirect-api=false, port-defined-argument-value{value=171, value-type=uint8}, port=EnableCond_x0}
        {enable-take-address=true, indirect-api=false, port-defined-argument-value{value=172, value-type=uint8}, port=EnableCond_x1}
        {enable-take-address=true, indirect-api=false, port-defined-argument-value{value=149, value-type=uint8}, port=EnableCond_reset}
        {enable-take-address=true, indirect-api=false, port-defined-argument-value{value=36, value-type=uint8}, port=EnableCond_ModeRequestDCDC}
        {enable-take-address=true, indirect-api=false, port-defined-argument-value{value=7, value-type=uint8}, port=EnableCond_BMS_status}
        {enable-take-address=true, indirect-api=false, port-defined-argument-value{value=85, value-type=uint8}, port=EnableCond_active}
        {enable-take-address=true, indirect-api=false, port-defined-argument-value{value=148, value-type=uint8}, port=EnableCond_requirements}
        {enable-take-address=true, indirect-api=false, port-defined-argument-value{value=135, value-type=uint8}, port=EnableCond_pedal}
        {enable-take-address=true, indirect-api=false, port-defined-argument-value{value=175, value-type=uint8}, port=EnableCond_x4}
        {enable-take-address=true, indirect-api=false, port-defined-argument-value{value=64, value-type=uint8}, port=EnableCond_Standby}
        {enable-take-address=true, indirect-api=false, port-defined-argument-value{value=176, value-type=uint8}, port=EnableCond_x5}
        {enable-take-address=true, indirect-api=false, port-defined-argument-value{value=173, value-type=uint8}, port=EnableCond_x2}
        {enable-take-address=true, indirect-api=false, port-defined-argument-value{value=174, value-type=uint8}, port=EnableCond_x3}
        {enable-take-address=true, indirect-api=false, port-defined-argument-value{value=162, value-type=uint8}, port=EnableCond_timer}
        {enable-take-address=true, indirect-api=false, port-defined-argument-value{value=103, value-type=uint8}, port=EnableCond_criteria}
        {enable-take-address=true, indirect-api=false, port-defined-argument-value{value=163, value-type=uint8}, port=EnableCond_times}
        {enable-take-address=true, indirect-api=false, port-defined-argument-value{value=38, value-type=uint8}, port=EnableCond_Non}
        {enable-take-address=true, indirect-api=false, port-defined-argument-value{value=102, value-type=uint8}, port=EnableCond_confirmation}
        {enable-take-address=true, indirect-api=false, port-defined-argument-value{value=166, value-type=uint8}, port=EnableCond_trigger}
        {enable-take-address=true, indirect-api=false, port-defined-argument-value{value=157, value-type=uint8}, port=EnableCond_simultaneously}
        {enable-take-address=true, indirect-api=false, port-defined-argument-value{value=27, value-type=uint8}, port=EnableCond_InActive}
        {enable-take-address=true, indirect-api=false, port-defined-argument-value{value=92, value-type=uint8}, port=EnableCond_battery}
        {enable-take-address=true, indirect-api=false, port-defined-argument-value{value=123, value-type=uint8}, port=EnableCond_main}
        {enable-take-address=true, indirect-api=false, port-defined-argument-value{value=115, value-type=uint8}, port=EnableCond_from}
        {enable-take-address=true, indirect-api=false, port-defined-argument-value{value=58, value-type=uint8}, port=EnableCond_Plug}
        {enable-take-address=true, indirect-api=false, port-defined-argument-value{value=170, value-type=uint8}, port=EnableCond_waked}
        {enable-take-address=true, indirect-api=false, port-defined-argument-value{value=95, value-type=uint8}, port=EnableCond_charge}
        {enable-take-address=true, indirect-api=false, port-defined-argument-value{value=142, value-type=uint8}, port=EnableCond_process}
        {enable-take-address=true, indirect-api=false, port-defined-argument-value{value=12, value-type=uint8}, port=EnableCond_Chargestatus}
        {enable-take-address=true, indirect-api=false, port-defined-argument-value{value=109, value-type=uint8}, port=EnableCond_during}
        {enable-take-address=true, indirect-api=false, port-defined-argument-value{value=31, value-type=uint8}, port=EnableCond_KL15e}
        {enable-take-address=true, indirect-api=false, port-defined-argument-value{value=132, value-type=uint8}, port=EnableCond_only}
        {enable-take-address=true, indirect-api=false, port-defined-argument-value{value=35, value-type=uint8}, port=EnableCond_MCU_VCUWorkMode}
        {enable-take-address=true, indirect-api=false, port-defined-argument-value{value=25, value-type=uint8}, port=EnableCond_High}
        {enable-take-address=true, indirect-api=false, port-defined-argument-value{value=67, value-type=uint8}, port=EnableCond_Torque}
        {enable-take-address=true, indirect-api=false, port-defined-argument-value{value=69, value-type=uint8}, port=EnableCond_V}
        {enable-take-address=true, indirect-api=false, port-defined-argument-value{value=154, value-type=uint8}, port=EnableCond_serviceNote}
        {enable-take-address=true, indirect-api=false, port-defined-argument-value{value=72, value-type=uint8}, port=EnableCond_VCU_BMS_Control_of_NegRelay}
        {enable-take-address=true, indirect-api=false, port-defined-argument-value{value=152, value-type=uint8}, port=EnableCond_sends}
        {enable-take-address=true, indirect-api=false, port-defined-argument-value{value=133, value-type=uint8}, port=EnableCond_opening}
        {enable-take-address=true, indirect-api=false, port-defined-argument-value{value=33, value-type=uint8}, port=EnableCond_LAN_001}
        {enable-take-address=true, indirect-api=false, port-defined-argument-value{value=119, value-type=uint8}, port=EnableCond_in}
        {enable-take-address=true, indirect-api=false, port-defined-argument-value{value=60, value-type=uint8}, port=EnableCond_Ready}
        {enable-take-address=true, indirect-api=false, port-defined-argument-value{value=10, value-type=uint8}, port=EnableCond_Buck}
        {enable-take-address=true, indirect-api=false, port-defined-argument-value{value=91, value-type=uint8}, port=EnableCond_are}
        {enable-take-address=true, indirect-api=false, port-defined-argument-value{value=120, value-type=uint8}, port=EnableCond_is}
        {enable-take-address=true, indirect-api=false, port-defined-argument-value{value=66, value-type=uint8}, port=EnableCond_The}
        {enable-take-address=true, indirect-api=false, port-defined-argument-value{value=151, value-type=uint8}, port=EnableCond_s}
        {enable-take-address=true, indirect-api=false, port-defined-argument-value{value=26, value-type=uint8}, port=EnableCond_If}
        {enable-take-address=true, indirect-api=false, port-defined-argument-value{value=150, value-type=uint8}, port=EnableCond_restored}
        {enable-take-address=true, indirect-api=false, port-defined-argument-value{value=0, value-type=uint8}, port=IndStatus_WarningIndicator}
        enable-take-address=true, indirect-api=false, port=DemMaster_0/GeneralEvtInfo
        {enable-take-address=true, indirect-api=false, port-defined-argument-value{value=0, value-type=uint8}, port=OpCycle_PowerCycle}
        enable-take-address=true, indirect-api=false, port=DemMaster_0/CBReadData_DID_0xf1a4_Date_And_Time_Minute
        enable-take-address=true, indirect-api=false, port=DemMaster_0/CBReadData_DID_0xf1a0_Ignition_Switch_Signal
        enable-take-address=true, indirect-api=false, port=DemMaster_0/CBReadData_DID_0x1d01_Accelerator_pedal_sensor_2_voltage
        enable-take-address=true, indirect-api=false, port=DemMaster_0/CBReadData_DID_0x1d11_Mainrealy1
        enable-take-address=true, indirect-api=false, port=DemMaster_0/CBReadData_DID_0x1d05_POD_OBC_OutputDCChargeCurrent
        enable-take-address=true, indirect-api=false, port=DemMaster_0/CBReadData_DID_0x1d01_Accelerator_pedal_sensor_1_voltage
        enable-take-address=true, indirect-api=false, port=DemMaster_0/CBReadData_DID_0x1d07_Electronic_lock_state
        enable-take-address=true, indirect-api=false, port=DemMaster_0/CBReadData_DID_0x1d09_New_Bit_Field
        enable-take-address=true, indirect-api=false, port=DemMaster_0/CBReadData_DID_0x1d01_VCU_VehicleSpeed
        enable-take-address=true, indirect-api=false, port=DemMaster_0/CBReadData_DID_0xf1a3_Vehicle_speed
        enable-take-address=true, indirect-api=false, port=DemMaster_0/CBReadData_DID_0x1d05_POD_OBC_InputACVoltage
        enable-take-address=true, indirect-api=false, port=DemMaster_0/CBReadData_DID_0xf1a2_Total_Odometer
        enable-take-address=true, indirect-api=false, port=DemMaster_0/CBReadData_DID_0xf1a5_VCU_HVStatus
        enable-take-address=true, indirect-api=false, port=DemMaster_0/CBReadData_DID_0xf1a7_Gear
        enable-take-address=true, indirect-api=false, port=DemMaster_0/CBReadData_ExtendedData_Fault_Aging_Counter
        enable-take-address=true, indirect-api=false, port=DemMaster_0/CBReadData_DID_0xf1a1_Battery_Voltage
        enable-take-address=true, indirect-api=false, port=DemMaster_0/CBReadData_DID_0xf1a4_Date_And_Time_Hour
        enable-take-address=true, indirect-api=false, port=DemMaster_0/CBReadData_DID_0xf1a4_Date_And_Time_Day
        enable-take-address=true, indirect-api=false, port=DemMaster_0/CBReadData_DID_0x1d01_VCU_AccelerationPedal
        enable-take-address=true, indirect-api=false, port=DemMaster_0/CBReadData_DID_0x1d05_POD_OBC_OutputDCChargeVoltage
        enable-take-address=true, indirect-api=false, port=DemMaster_0/CBReadData_ExtendedData_Fault_Ocurrence_Counter
        enable-take-address=true, indirect-api=false, port=DemMaster_0/CBReadData_DID_0x1d08_VCU_HVIL
        enable-take-address=true, indirect-api=false, port=DemMaster_0/CBReadData_DID_0xf1a4_Date_And_Time_Year
        enable-take-address=true, indirect-api=false, port=DemMaster_0/CBReadData_DID_0xf1a4_Date_And_Time_Month
        enable-take-address=true, indirect-api=false, port=DemMaster_0/CBReadData_DID_0xf1a4_Date_And_Time_Second
        enable-take-address=true, indirect-api=false, port=DemMaster_0/CBReadData_DID_0x1d11_Mainrelay2
        enable-take-address=true, indirect-api=false, port=DemMaster_0/CBReadData_ExtendedData_Fault_Aged_Counter
        enable-take-address=true, indirect-api=false, port=DemMaster_0/CBReadData_DID_0x1d05_VCU_OBC_ChargeCurrentCommand
        enable-take-address=true, indirect-api=false, port=DemMaster_0/CBReadData_DID_0xf1a6_SOC
      18 x runnable:
        Dem_MasterMainFunction
          29 x sync call, all with timeout=0:
            OpServerCallDem_MasterMainFunction_ReadData_CBReadData_DID_0xf1a4_Date_And_Time_Minute: operation=CBReadData_DID_0xf1a4_Date_And_Time_Minute.ReadData
            OpServerCallDem_MasterMainFunction_ReadData_CBReadData_DID_0xf1a0_Ignition_Switch_Signal: operation=CBReadData_DID_0xf1a0_Ignition_Switch_Signal.ReadData
            OpServerCallDem_MasterMainFunction_ReadData_CBReadData_DID_0x1d01_Accelerator_pedal_sensor_2_voltage: operation=CBReadData_DID_0x1d01_Accelerator_pedal_sensor_2_voltage.ReadData
            OpServerCallDem_MasterMainFunction_ReadData_CBReadData_DID_0x1d11_Mainrealy1: operation=CBReadData_DID_0x1d11_Mainrealy1.ReadData
            OpServerCallDem_MasterMainFunction_ReadData_CBReadData_DID_0x1d05_POD_OBC_OutputDCChargeCurrent: operation=CBReadData_DID_0x1d05_POD_OBC_OutputDCChargeCurrent.ReadData
            OpServerCallDem_MasterMainFunction_ReadData_CBReadData_DID_0x1d01_Accelerator_pedal_sensor_1_voltage: operation=CBReadData_DID_0x1d01_Accelerator_pedal_sensor_1_voltage.ReadData
            OpServerCallDem_MasterMainFunction_ReadData_CBReadData_DID_0x1d07_Electronic_lock_state: operation=CBReadData_DID_0x1d07_Electronic_lock_state.ReadData
            OpServerCallDem_MasterMainFunction_ReadData_CBReadData_DID_0x1d09_New_Bit_Field: operation=CBReadData_DID_0x1d09_New_Bit_Field.ReadData
            OpServerCallDem_MasterMainFunction_ReadData_CBReadData_DID_0x1d01_VCU_VehicleSpeed: operation=CBReadData_DID_0x1d01_VCU_VehicleSpeed.ReadData
            OpServerCallDem_MasterMainFunction_ReadData_CBReadData_DID_0xf1a3_Vehicle_speed: operation=CBReadData_DID_0xf1a3_Vehicle_speed.ReadData
            OpServerCallDem_MasterMainFunction_ReadData_CBReadData_DID_0x1d05_POD_OBC_InputACVoltage: operation=CBReadData_DID_0x1d05_POD_OBC_InputACVoltage.ReadData
            OpServerCallDem_MasterMainFunction_ReadData_CBReadData_DID_0xf1a2_Total_Odometer: operation=CBReadData_DID_0xf1a2_Total_Odometer.ReadData
            OpServerCallDem_MasterMainFunction_ReadData_CBReadData_DID_0xf1a5_VCU_HVStatus: operation=CBReadData_DID_0xf1a5_VCU_HVStatus.ReadData
            OpServerCallDem_MasterMainFunction_ReadData_CBReadData_DID_0xf1a7_Gear: operation=CBReadData_DID_0xf1a7_Gear.ReadData
            OpServerCallDem_MasterMainFunction_ReadData_CBReadData_ExtendedData_Fault_Aging_Counter: operation=CBReadData_ExtendedData_Fault_Aging_Counter.ReadData
            OpServerCallDem_MasterMainFunction_ReadData_CBReadData_DID_0xf1a1_Battery_Voltage: operation=CBReadData_DID_0xf1a1_Battery_Voltage.ReadData
            OpServerCallDem_MasterMainFunction_ReadData_CBReadData_DID_0xf1a4_Date_And_Time_Hour: operation=CBReadData_DID_0xf1a4_Date_And_Time_Hour.ReadData
            OpServerCallDem_MasterMainFunction_ReadData_CBReadData_DID_0xf1a4_Date_And_Time_Day: operation=CBReadData_DID_0xf1a4_Date_And_Time_Day.ReadData
            OpServerCallDem_MasterMainFunction_ReadData_CBReadData_DID_0x1d01_VCU_AccelerationPedal: operation=CBReadData_DID_0x1d01_VCU_AccelerationPedal.ReadData
            OpServerCallDem_MasterMainFunction_ReadData_CBReadData_DID_0x1d05_POD_OBC_OutputDCChargeVoltage: operation=CBReadData_DID_0x1d05_POD_OBC_OutputDCChargeVoltage.ReadData
            OpServerCallDem_MasterMainFunction_ReadData_CBReadData_ExtendedData_Fault_Ocurrence_Counter: operation=CBReadData_ExtendedData_Fault_Ocurrence_Counter.ReadData
            OpServerCallDem_MasterMainFunction_ReadData_CBReadData_DID_0x1d08_VCU_HVIL: operation=CBReadData_DID_0x1d08_VCU_HVIL.ReadData
            OpServerCallDem_MasterMainFunction_ReadData_CBReadData_DID_0xf1a4_Date_And_Time_Year: operation=CBReadData_DID_0xf1a4_Date_And_Time_Year.ReadData
            OpServerCallDem_MasterMainFunction_ReadData_CBReadData_DID_0xf1a4_Date_And_Time_Month: operation=CBReadData_DID_0xf1a4_Date_And_Time_Month.ReadData
            OpServerCallDem_MasterMainFunction_ReadData_CBReadData_DID_0xf1a4_Date_And_Time_Second: operation=CBReadData_DID_0xf1a4_Date_And_Time_Second.ReadData
            OpServerCallDem_MasterMainFunction_ReadData_CBReadData_DID_0x1d11_Mainrelay2: operation=CBReadData_DID_0x1d11_Mainrelay2.ReadData
            OpServerCallDem_MasterMainFunction_ReadData_CBReadData_ExtendedData_Fault_Aged_Counter: operation=CBReadData_ExtendedData_Fault_Aged_Counter.ReadData
            OpServerCallDem_MasterMainFunction_ReadData_CBReadData_DID_0x1d05_VCU_OBC_ChargeCurrentCommand: operation=CBReadData_DID_0x1d05_VCU_OBC_ChargeCurrentCommand.ReadData
            OpServerCallDem_MasterMainFunction_ReadData_CBReadData_DID_0xf1a6_SOC: operation=CBReadData_DID_0xf1a6_SOC.ReadData
        PostRunRequested: can-be-invoked-concurrently=true, symbol=Dem_PostRunRequested
        GetDTCStatusAvailabilityMask: can-be-invoked-concurrently=true, symbol=Dem_GetDTCStatusAvailabilityMask
        SetEnableCondition: can-be-invoked-concurrently=true, symbol=Dem_SetEnableCondition
        GetIndicatorStatus: can-be-invoked-concurrently=true, symbol=Dem_GetIndicatorStatus
        GetEventUdsStatus: can-be-invoked-concurrently=true, symbol=Dem_GetEventUdsStatus
        GetEventStatus: can-be-invoked-concurrently=true, symbol=Dem_GetEventUdsStatus
        GetEventFailed: can-be-invoked-concurrently=true, symbol=Dem_GetEventFailed
        GetEventTested: can-be-invoked-concurrently=true, symbol=Dem_GetEventTested
        GetDTCOfEvent: can-be-invoked-concurrently=true, symbol=Dem_GetDTCOfEvent
        GetFaultDetectionCounter: can-be-invoked-concurrently=true, symbol=Dem_GetFaultDetectionCounter
        GetEventFreezeFrameDataEx: can-be-invoked-concurrently=true, symbol=Dem_GetEventFreezeFrameDataEx
        GetEventExtendedDataRecordEx: can-be-invoked-concurrently=true, symbol=Dem_GetEventExtendedDataRecordEx
        GetEventEnableCondition: can-be-invoked-concurrently=true, symbol=Dem_GetEventEnableCondition
        GetDebouncingOfEvent: can-be-invoked-concurrently=true, symbol=Dem_GetDebouncingOfEvent
        GetMonitorStatus: can-be-invoked-concurrently=true, symbol=Dem_GetMonitorStatus
        GetOperationCycleState: can-be-invoked-concurrently=true, symbol=Dem_GetOperationCycleState
        SetOperationCycleState: can-be-invoked-concurrently=true, symbol=Dem_SetOperationCycleState
  swc implementation DemMaster_0Implementation: programming-language=C, behavior=DemMaster_0InternalBehavior
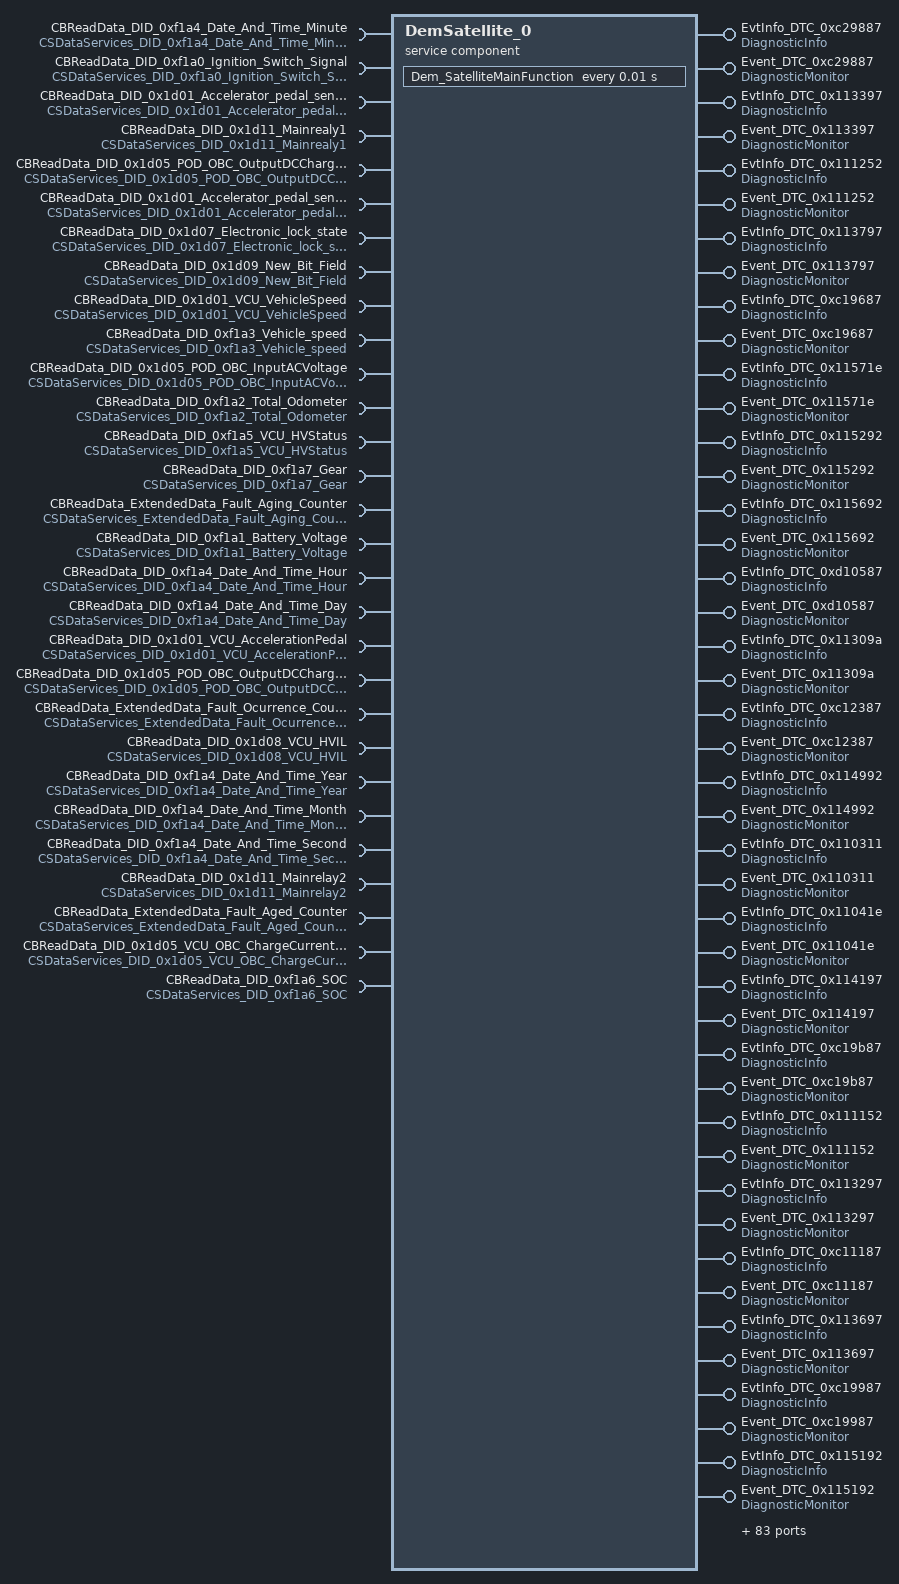
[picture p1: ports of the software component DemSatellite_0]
  service sw component type DemSatellite_0: category=SERVICE_COMPONENT
    127 x provide port:
      EvtInfo_DTC_0xc29887: provided-interface=DiagnosticInfo
      Event_DTC_0xc29887: provided-interface=DiagnosticMonitor
      EvtInfo_DTC_0x113397: provided-interface=DiagnosticInfo
      Event_DTC_0x113397: provided-interface=DiagnosticMonitor
      EvtInfo_DTC_0x111252: provided-interface=DiagnosticInfo
      Event_DTC_0x111252: provided-interface=DiagnosticMonitor
      EvtInfo_DTC_0x113797: provided-interface=DiagnosticInfo
      Event_DTC_0x113797: provided-interface=DiagnosticMonitor
      EvtInfo_DTC_0xc19687: provided-interface=DiagnosticInfo
      Event_DTC_0xc19687: provided-interface=DiagnosticMonitor
      EvtInfo_DTC_0x11571e: provided-interface=DiagnosticInfo
      Event_DTC_0x11571e: provided-interface=DiagnosticMonitor
      EvtInfo_DTC_0x115292: provided-interface=DiagnosticInfo
      Event_DTC_0x115292: provided-interface=DiagnosticMonitor
      EvtInfo_DTC_0x115692: provided-interface=DiagnosticInfo
      Event_DTC_0x115692: provided-interface=DiagnosticMonitor
      EvtInfo_DTC_0xd10587: provided-interface=DiagnosticInfo
      Event_DTC_0xd10587: provided-interface=DiagnosticMonitor
      EvtInfo_DTC_0x11309a: provided-interface=DiagnosticInfo
      Event_DTC_0x11309a: provided-interface=DiagnosticMonitor
      EvtInfo_DTC_0xc12387: provided-interface=DiagnosticInfo
      Event_DTC_0xc12387: provided-interface=DiagnosticMonitor
      EvtInfo_DTC_0x114992: provided-interface=DiagnosticInfo
      Event_DTC_0x114992: provided-interface=DiagnosticMonitor
      EvtInfo_DTC_0x110311: provided-interface=DiagnosticInfo
      Event_DTC_0x110311: provided-interface=DiagnosticMonitor
      EvtInfo_DTC_0x11041e: provided-interface=DiagnosticInfo
      Event_DTC_0x11041e: provided-interface=DiagnosticMonitor
      EvtInfo_DTC_0x114197: provided-interface=DiagnosticInfo
      Event_DTC_0x114197: provided-interface=DiagnosticMonitor
      EvtInfo_DTC_0xc19b87: provided-interface=DiagnosticInfo
      Event_DTC_0xc19b87: provided-interface=DiagnosticMonitor
      EvtInfo_DTC_0x111152: provided-interface=DiagnosticInfo
      Event_DTC_0x111152: provided-interface=DiagnosticMonitor
      EvtInfo_DTC_0x113297: provided-interface=DiagnosticInfo
      Event_DTC_0x113297: provided-interface=DiagnosticMonitor
      EvtInfo_DTC_0xc11187: provided-interface=DiagnosticInfo
      Event_DTC_0xc11187: provided-interface=DiagnosticMonitor
      EvtInfo_DTC_0x113697: provided-interface=DiagnosticInfo
      Event_DTC_0x113697: provided-interface=DiagnosticMonitor
      EvtInfo_DTC_0xc19987: provided-interface=DiagnosticInfo
      Event_DTC_0xc19987: provided-interface=DiagnosticMonitor
      EvtInfo_DTC_0x115192: provided-interface=DiagnosticInfo
      Event_DTC_0x115192: provided-interface=DiagnosticMonitor
      EvtInfo_DTC_0x115592: provided-interface=DiagnosticInfo
      Event_DTC_0x115592: provided-interface=DiagnosticMonitor
      EvtInfo_DTC_0xc07388: provided-interface=DiagnosticInfo
      Event_DTC_0xc07388: provided-interface=DiagnosticMonitor
      EvtInfo_DTC_0xc10387: provided-interface=DiagnosticInfo
      Event_DTC_0xc10387: provided-interface=DiagnosticMonitor
      EvtInfo_DTC_0x114892: provided-interface=DiagnosticInfo
      Event_DTC_0x114892: provided-interface=DiagnosticMonitor
      EvtInfo_DTC_0x114497: provided-interface=DiagnosticInfo
      Event_DTC_0x114497: provided-interface=DiagnosticMonitor
      EvtInfo_DTC_0x110211: provided-interface=DiagnosticInfo
      Event_DTC_0x110211: provided-interface=DiagnosticMonitor
      EvtInfo_DTC_0x114097: provided-interface=DiagnosticInfo
      Event_DTC_0x114097: provided-interface=DiagnosticMonitor
      EvtInfo_DTC_0x115816: provided-interface=DiagnosticInfo
      Event_DTC_0x115816: provided-interface=DiagnosticMonitor
      EvtInfo_DTC_0x110b1e: provided-interface=DiagnosticInfo
      Event_DTC_0x110b1e: provided-interface=DiagnosticMonitor
      EvtInfo_DTC_0x113597: provided-interface=DiagnosticInfo
      Event_DTC_0x113597: provided-interface=DiagnosticMonitor
      EvtInfo_DTC_0x908017: provided-interface=DiagnosticInfo
      Event_DTC_0x908017: provided-interface=DiagnosticMonitor
      EvtInfo_DTC_0x113997: provided-interface=DiagnosticInfo
      Event_DTC_0x113997: provided-interface=DiagnosticMonitor
      EvtInfo_DTC_0x11591e: provided-interface=DiagnosticInfo
      Event_DTC_0x11591e: provided-interface=DiagnosticMonitor
      EvtInfo_DTC_0x115492: provided-interface=DiagnosticInfo
      Event_DTC_0x115492: provided-interface=DiagnosticMonitor
      EvtInfo_DTC_0xc11087: provided-interface=DiagnosticInfo
      Event_DTC_0xc11087: provided-interface=DiagnosticMonitor
      EvtInfo_DTC_0x113197: provided-interface=DiagnosticInfo
      Event_DTC_0x113197: provided-interface=DiagnosticMonitor
      EvtInfo_DTC_0x115092: provided-interface=DiagnosticInfo
      Event_DTC_0x115092: provided-interface=DiagnosticMonitor
      EvtInfo_DTC_0xc07488: provided-interface=DiagnosticInfo
      Event_DTC_0xc07488: provided-interface=DiagnosticMonitor
      EvtInfo_DTC_0x114397: provided-interface=DiagnosticInfo
      Event_DTC_0x114397: provided-interface=DiagnosticMonitor
      EvtInfo_DTC_0xc12987: provided-interface=DiagnosticInfo
      Event_DTC_0xc12987: provided-interface=DiagnosticMonitor
      EvtInfo_DTC_0x110112: provided-interface=DiagnosticInfo
      Event_DTC_0x110112: provided-interface=DiagnosticMonitor
      EvtInfo_DTC_0xc14087: provided-interface=DiagnosticInfo
      Event_DTC_0xc14087: provided-interface=DiagnosticMonitor
      EvtInfo_DTC_0xc12187: provided-interface=DiagnosticInfo
      Event_DTC_0xc12187: provided-interface=DiagnosticMonitor
      EvtInfo_DTC_0x114792: provided-interface=DiagnosticInfo
      Event_DTC_0x114792: provided-interface=DiagnosticMonitor
      EvtInfo_DTC_0x11291c: provided-interface=DiagnosticInfo
      Event_DTC_0x11291c: provided-interface=DiagnosticMonitor
      EvtInfo_DTC_0xc11d87: provided-interface=DiagnosticInfo
      Event_DTC_0xc11d87: provided-interface=DiagnosticMonitor
      EvtInfo_DTC_0x110a1e: provided-interface=DiagnosticInfo
      Event_DTC_0x110a1e: provided-interface=DiagnosticMonitor
      EvtInfo_DTC_0x111352: provided-interface=DiagnosticInfo
      Event_DTC_0x111352: provided-interface=DiagnosticMonitor
      EvtInfo_DTC_0x113497: provided-interface=DiagnosticInfo
      Event_DTC_0x113497: provided-interface=DiagnosticMonitor
      EvtInfo_DTC_0x908116: provided-interface=DiagnosticInfo
      Event_DTC_0x908116: provided-interface=DiagnosticMonitor
      EvtInfo_DTC_0x113897: provided-interface=DiagnosticInfo
      Event_DTC_0x113897: provided-interface=DiagnosticMonitor
      EvtInfo_DTC_0x115392: provided-interface=DiagnosticInfo
      Event_DTC_0x115392: provided-interface=DiagnosticMonitor
      EvtInfo_DTC_0x111f16: provided-interface=DiagnosticInfo
      Event_DTC_0x111f16: provided-interface=DiagnosticMonitor
      EvtInfo_DTC_0x111e71: provided-interface=DiagnosticInfo
      Event_DTC_0x111e71: provided-interface=DiagnosticMonitor
      EvtInfo_DTC_0x114697: provided-interface=DiagnosticInfo
      Event_DTC_0x114697: provided-interface=DiagnosticMonitor
      EvtInfo_DTC_0x110012: provided-interface=DiagnosticInfo
      Event_DTC_0x110012: provided-interface=DiagnosticMonitor
      EvtInfo_DTC_0xc16687: provided-interface=DiagnosticInfo
      Event_DTC_0xc16687: provided-interface=DiagnosticMonitor
      EvtInfo_DTC_0xc14787: provided-interface=DiagnosticInfo
      Event_DTC_0xc14787: provided-interface=DiagnosticMonitor
      EvtInfo_DTC_0x114571: provided-interface=DiagnosticInfo
      Event_DTC_0x114571: provided-interface=DiagnosticMonitor
      EvtInfo_DTC_0x11281e: provided-interface=DiagnosticInfo
      Event_DTC_0x11281e: provided-interface=DiagnosticMonitor
      EvtInfo_DTC_0x114297: provided-interface=DiagnosticInfo
      Event_DTC_0x114297: provided-interface=DiagnosticMonitor
      GeneralEvtInfo: provided-interface=GeneralDiagnosticInfo
    29 x require port:
      CBReadData_DID_0xf1a4_Date_And_Time_Minute: required-interface=CSDataServices_DID_0xf1a4_Date_And_Time_Minute
      CBReadData_DID_0xf1a0_Ignition_Switch_Signal: required-interface=CSDataServices_DID_0xf1a0_Ignition_Switch_Signal
      CBReadData_DID_0x1d01_Accelerator_pedal_sensor_2_voltage: required-interface=CSDataServices_DID_0x1d01_Accelerator_pedal_sensor_2_voltage
      CBReadData_DID_0x1d11_Mainrealy1: required-interface=CSDataServices_DID_0x1d11_Mainrealy1
      CBReadData_DID_0x1d05_POD_OBC_OutputDCChargeCurrent: required-interface=CSDataServices_DID_0x1d05_POD_OBC_OutputDCChargeCurrent
      CBReadData_DID_0x1d01_Accelerator_pedal_sensor_1_voltage: required-interface=CSDataServices_DID_0x1d01_Accelerator_pedal_sensor_1_voltage
      CBReadData_DID_0x1d07_Electronic_lock_state: required-interface=CSDataServices_DID_0x1d07_Electronic_lock_state
      CBReadData_DID_0x1d09_New_Bit_Field: required-interface=CSDataServices_DID_0x1d09_New_Bit_Field
      CBReadData_DID_0x1d01_VCU_VehicleSpeed: required-interface=CSDataServices_DID_0x1d01_VCU_VehicleSpeed
      CBReadData_DID_0xf1a3_Vehicle_speed: required-interface=CSDataServices_DID_0xf1a3_Vehicle_speed
      CBReadData_DID_0x1d05_POD_OBC_InputACVoltage: required-interface=CSDataServices_DID_0x1d05_POD_OBC_InputACVoltage
      CBReadData_DID_0xf1a2_Total_Odometer: required-interface=CSDataServices_DID_0xf1a2_Total_Odometer
      CBReadData_DID_0xf1a5_VCU_HVStatus: required-interface=CSDataServices_DID_0xf1a5_VCU_HVStatus
      CBReadData_DID_0xf1a7_Gear: required-interface=CSDataServices_DID_0xf1a7_Gear
      CBReadData_ExtendedData_Fault_Aging_Counter: required-interface=CSDataServices_ExtendedData_Fault_Aging_Counter
      CBReadData_DID_0xf1a1_Battery_Voltage: required-interface=CSDataServices_DID_0xf1a1_Battery_Voltage
      CBReadData_DID_0xf1a4_Date_And_Time_Hour: required-interface=CSDataServices_DID_0xf1a4_Date_And_Time_Hour
      CBReadData_DID_0xf1a4_Date_And_Time_Day: required-interface=CSDataServices_DID_0xf1a4_Date_And_Time_Day
      CBReadData_DID_0x1d01_VCU_AccelerationPedal: required-interface=CSDataServices_DID_0x1d01_VCU_AccelerationPedal
      CBReadData_DID_0x1d05_POD_OBC_OutputDCChargeVoltage: required-interface=CSDataServices_DID_0x1d05_POD_OBC_OutputDCChargeVoltage
      CBReadData_ExtendedData_Fault_Ocurrence_Counter: required-interface=CSDataServices_ExtendedData_Fault_Ocurrence_Counter
      CBReadData_DID_0x1d08_VCU_HVIL: required-interface=CSDataServices_DID_0x1d08_VCU_HVIL
      CBReadData_DID_0xf1a4_Date_And_Time_Year: required-interface=CSDataServices_DID_0xf1a4_Date_And_Time_Year
      CBReadData_DID_0xf1a4_Date_And_Time_Month: required-interface=CSDataServices_DID_0xf1a4_Date_And_Time_Month
      CBReadData_DID_0xf1a4_Date_And_Time_Second: required-interface=CSDataServices_DID_0xf1a4_Date_And_Time_Second
      CBReadData_DID_0x1d11_Mainrelay2: required-interface=CSDataServices_DID_0x1d11_Mainrelay2
      CBReadData_ExtendedData_Fault_Aged_Counter: required-interface=CSDataServices_ExtendedData_Fault_Aged_Counter
      CBReadData_DID_0x1d05_VCU_OBC_ChargeCurrentCommand: required-interface=CSDataServices_DID_0x1d05_VCU_OBC_ChargeCurrentCommand
      CBReadData_DID_0xf1a6_SOC: required-interface=CSDataServices_DID_0xf1a6_SOC
    behavior DemSatellite_0InternalBehavior: handle-termination-and-restart=NO-SUPPORT, included-data-type-set=data-type=[Dem_EventIdType, Dem_RatioIdType, Dem_EventStatusType, Dem_UdsStatusByteType, Dem_DTCFormatType, Dem_InitMonitorReasonType, Dem_OperationCycleStateType, Dem_DTCStatusMaskType, Dem_IndicatorStatusType, Dem_MaxDataValueType, Dem_DTCKindType, Dem_DTCGroupType, Dem_IumprDenomCondIdType, Dem_IumprDenomCondStatusType, Dem_DebounceResetStatusType, Dem_DebouncingStateType, Dem_IumprReadinessGroupType, Dem_DTRControlType, Dem_DTCSeverityType, Dem_MonitorStatusType]
      timing event Timer_Dem_SatelliteMainFunction: start-on-event=Dem_SatelliteMainFunction, period=0.01
      1397 x operation invoked event:
        OpEventGetEventUdsStatus_GetEventUdsStatus_EvtInfo_DTC_0xc29887: start-on-event=DemSatellite_0InternalBehavior/GetEventUdsStatus, operation=EvtInfo_DTC_0xc29887.GetEventUdsStatus
        OpEventGetEventUdsStatus_GetEventUdsStatus_Event_DTC_0xc29887: start-on-event=DemSatellite_0InternalBehavior/GetEventUdsStatus, operation=Event_DTC_0xc29887.GetEventUdsStatus
        OpEventGetEventUdsStatus_GetEventUdsStatus_EvtInfo_DTC_0x113397: start-on-event=DemSatellite_0InternalBehavior/GetEventUdsStatus, operation=EvtInfo_DTC_0x113397.GetEventUdsStatus
        OpEventGetEventUdsStatus_GetEventUdsStatus_Event_DTC_0x113397: start-on-event=DemSatellite_0InternalBehavior/GetEventUdsStatus, operation=Event_DTC_0x113397.GetEventUdsStatus
        OpEventGetEventUdsStatus_GetEventUdsStatus_EvtInfo_DTC_0x111252: start-on-event=DemSatellite_0InternalBehavior/GetEventUdsStatus, operation=EvtInfo_DTC_0x111252.GetEventUdsStatus
        OpEventGetEventUdsStatus_GetEventUdsStatus_Event_DTC_0x111252: start-on-event=DemSatellite_0InternalBehavior/GetEventUdsStatus, operation=Event_DTC_0x111252.GetEventUdsStatus
        OpEventGetEventUdsStatus_GetEventUdsStatus_EvtInfo_DTC_0x113797: start-on-event=DemSatellite_0InternalBehavior/GetEventUdsStatus, operation=EvtInfo_DTC_0x113797.GetEventUdsStatus
        OpEventGetEventUdsStatus_GetEventUdsStatus_Event_DTC_0x113797: start-on-event=DemSatellite_0InternalBehavior/GetEventUdsStatus, operation=Event_DTC_0x113797.GetEventUdsStatus
        OpEventGetEventUdsStatus_GetEventUdsStatus_EvtInfo_DTC_0xc19687: start-on-event=DemSatellite_0InternalBehavior/GetEventUdsStatus, operation=EvtInfo_DTC_0xc19687.GetEventUdsStatus
        OpEventGetEventUdsStatus_GetEventUdsStatus_Event_DTC_0xc19687: start-on-event=DemSatellite_0InternalBehavior/GetEventUdsStatus, operation=Event_DTC_0xc19687.GetEventUdsStatus
        OpEventGetEventUdsStatus_GetEventUdsStatus_EvtInfo_DTC_0x11571e: start-on-event=DemSatellite_0InternalBehavior/GetEventUdsStatus, operation=EvtInfo_DTC_0x11571e.GetEventUdsStatus
        OpEventGetEventUdsStatus_GetEventUdsStatus_Event_DTC_0x11571e: start-on-event=DemSatellite_0InternalBehavior/GetEventUdsStatus, operation=Event_DTC_0x11571e.GetEventUdsStatus
        OpEventGetEventUdsStatus_GetEventUdsStatus_EvtInfo_DTC_0x115292: start-on-event=DemSatellite_0InternalBehavior/GetEventUdsStatus, operation=EvtInfo_DTC_0x115292.GetEventUdsStatus
        OpEventGetEventUdsStatus_GetEventUdsStatus_Event_DTC_0x115292: start-on-event=DemSatellite_0InternalBehavior/GetEventUdsStatus, operation=Event_DTC_0x115292.GetEventUdsStatus
        OpEventGetEventUdsStatus_GetEventUdsStatus_EvtInfo_DTC_0x115692: start-on-event=DemSatellite_0InternalBehavior/GetEventUdsStatus, operation=EvtInfo_DTC_0x115692.GetEventUdsStatus
        OpEventGetEventUdsStatus_GetEventUdsStatus_Event_DTC_0x115692: start-on-event=DemSatellite_0InternalBehavior/GetEventUdsStatus, operation=Event_DTC_0x115692.GetEventUdsStatus
        OpEventGetEventUdsStatus_GetEventUdsStatus_EvtInfo_DTC_0xd10587: start-on-event=DemSatellite_0InternalBehavior/GetEventUdsStatus, operation=EvtInfo_DTC_0xd10587.GetEventUdsStatus
        OpEventGetEventUdsStatus_GetEventUdsStatus_Event_DTC_0xd10587: start-on-event=DemSatellite_0InternalBehavior/GetEventUdsStatus, operation=Event_DTC_0xd10587.GetEventUdsStatus
        OpEventGetEventUdsStatus_GetEventUdsStatus_EvtInfo_DTC_0x11309a: start-on-event=DemSatellite_0InternalBehavior/GetEventUdsStatus, operation=EvtInfo_DTC_0x11309a.GetEventUdsStatus
        OpEventGetEventUdsStatus_GetEventUdsStatus_Event_DTC_0x11309a: start-on-event=DemSatellite_0InternalBehavior/GetEventUdsStatus, operation=Event_DTC_0x11309a.GetEventUdsStatus
        OpEventGetEventUdsStatus_GetEventUdsStatus_EvtInfo_DTC_0xc12387: start-on-event=DemSatellite_0InternalBehavior/GetEventUdsStatus, operation=EvtInfo_DTC_0xc12387.GetEventUdsStatus
        OpEventGetEventUdsStatus_GetEventUdsStatus_Event_DTC_0xc12387: start-on-event=DemSatellite_0InternalBehavior/GetEventUdsStatus, operation=Event_DTC_0xc12387.GetEventUdsStatus
        OpEventGetEventUdsStatus_GetEventUdsStatus_EvtInfo_DTC_0x114992: start-on-event=DemSatellite_0InternalBehavior/GetEventUdsStatus, operation=EvtInfo_DTC_0x114992.GetEventUdsStatus
        OpEventGetEventUdsStatus_GetEventUdsStatus_Event_DTC_0x114992: start-on-event=DemSatellite_0InternalBehavior/GetEventUdsStatus, operation=Event_DTC_0x114992.GetEventUdsStatus
        OpEventGetEventUdsStatus_GetEventUdsStatus_EvtInfo_DTC_0x110311: start-on-event=DemSatellite_0InternalBehavior/GetEventUdsStatus, operation=EvtInfo_DTC_0x110311.GetEventUdsStatus
        OpEventGetEventUdsStatus_GetEventUdsStatus_Event_DTC_0x110311: start-on-event=DemSatellite_0InternalBehavior/GetEventUdsStatus, operation=Event_DTC_0x110311.GetEventUdsStatus
        OpEventGetEventUdsStatus_GetEventUdsStatus_EvtInfo_DTC_0x11041e: start-on-event=DemSatellite_0InternalBehavior/GetEventUdsStatus, operation=EvtInfo_DTC_0x11041e.GetEventUdsStatus
        OpEventGetEventUdsStatus_GetEventUdsStatus_Event_DTC_0x11041e: start-on-event=DemSatellite_0InternalBehavior/GetEventUdsStatus, operation=Event_DTC_0x11041e.GetEventUdsStatus
        OpEventGetEventUdsStatus_GetEventUdsStatus_EvtInfo_DTC_0x114197: start-on-event=DemSatellite_0InternalBehavior/GetEventUdsStatus, operation=EvtInfo_DTC_0x114197.GetEventUdsStatus
        OpEventGetEventUdsStatus_GetEventUdsStatus_Event_DTC_0x114197: start-on-event=DemSatellite_0InternalBehavior/GetEventUdsStatus, operation=Event_DTC_0x114197.GetEventUdsStatus
        OpEventGetEventUdsStatus_GetEventUdsStatus_EvtInfo_DTC_0xc19b87: start-on-event=DemSatellite_0InternalBehavior/GetEventUdsStatus, operation=EvtInfo_DTC_0xc19b87.GetEventUdsStatus
        OpEventGetEventUdsStatus_GetEventUdsStatus_Event_DTC_0xc19b87: start-on-event=DemSatellite_0InternalBehavior/GetEventUdsStatus, operation=Event_DTC_0xc19b87.GetEventUdsStatus
        OpEventGetEventUdsStatus_GetEventUdsStatus_EvtInfo_DTC_0x111152: start-on-event=DemSatellite_0InternalBehavior/GetEventUdsStatus, operation=EvtInfo_DTC_0x111152.GetEventUdsStatus
        OpEventGetEventUdsStatus_GetEventUdsStatus_Event_DTC_0x111152: start-on-event=DemSatellite_0InternalBehavior/GetEventUdsStatus, operation=Event_DTC_0x111152.GetEventUdsStatus
        OpEventGetEventUdsStatus_GetEventUdsStatus_EvtInfo_DTC_0x113297: start-on-event=DemSatellite_0InternalBehavior/GetEventUdsStatus, operation=EvtInfo_DTC_0x113297.GetEventUdsStatus
        OpEventGetEventUdsStatus_GetEventUdsStatus_Event_DTC_0x113297: start-on-event=DemSatellite_0InternalBehavior/GetEventUdsStatus, operation=Event_DTC_0x113297.GetEventUdsStatus
        OpEventGetEventUdsStatus_GetEventUdsStatus_EvtInfo_DTC_0xc11187: start-on-event=DemSatellite_0InternalBehavior/GetEventUdsStatus, operation=EvtInfo_DTC_0xc11187.GetEventUdsStatus
        OpEventGetEventUdsStatus_GetEventUdsStatus_Event_DTC_0xc11187: start-on-event=DemSatellite_0InternalBehavior/GetEventUdsStatus, operation=Event_DTC_0xc11187.GetEventUdsStatus
        OpEventGetEventUdsStatus_GetEventUdsStatus_EvtInfo_DTC_0x113697: start-on-event=DemSatellite_0InternalBehavior/GetEventUdsStatus, operation=EvtInfo_DTC_0x113697.GetEventUdsStatus
        OpEventGetEventUdsStatus_GetEventUdsStatus_Event_DTC_0x113697: start-on-event=DemSatellite_0InternalBehavior/GetEventUdsStatus, operation=Event_DTC_0x113697.GetEventUdsStatus
        OpEventGetEventUdsStatus_GetEventUdsStatus_EvtInfo_DTC_0xc19987: start-on-event=DemSatellite_0InternalBehavior/GetEventUdsStatus, operation=EvtInfo_DTC_0xc19987.GetEventUdsStatus
        OpEventGetEventUdsStatus_GetEventUdsStatus_Event_DTC_0xc19987: start-on-event=DemSatellite_0InternalBehavior/GetEventUdsStatus, operation=Event_DTC_0xc19987.GetEventUdsStatus
        OpEventGetEventUdsStatus_GetEventUdsStatus_EvtInfo_DTC_0x115192: start-on-event=DemSatellite_0InternalBehavior/GetEventUdsStatus, operation=EvtInfo_DTC_0x115192.GetEventUdsStatus
        OpEventGetEventUdsStatus_GetEventUdsStatus_Event_DTC_0x115192: start-on-event=DemSatellite_0InternalBehavior/GetEventUdsStatus, operation=Event_DTC_0x115192.GetEventUdsStatus
        OpEventGetEventUdsStatus_GetEventUdsStatus_EvtInfo_DTC_0x115592: start-on-event=DemSatellite_0InternalBehavior/GetEventUdsStatus, operation=EvtInfo_DTC_0x115592.GetEventUdsStatus
        OpEventGetEventUdsStatus_GetEventUdsStatus_Event_DTC_0x115592: start-on-event=DemSatellite_0InternalBehavior/GetEventUdsStatus, operation=Event_DTC_0x115592.GetEventUdsStatus
        OpEventGetEventUdsStatus_GetEventUdsStatus_EvtInfo_DTC_0xc07388: start-on-event=DemSatellite_0InternalBehavior/GetEventUdsStatus, operation=EvtInfo_DTC_0xc07388.GetEventUdsStatus
        OpEventGetEventUdsStatus_GetEventUdsStatus_Event_DTC_0xc07388: start-on-event=DemSatellite_0InternalBehavior/GetEventUdsStatus, operation=Event_DTC_0xc07388.GetEventUdsStatus
        OpEventGetEventUdsStatus_GetEventUdsStatus_EvtInfo_DTC_0xc10387: start-on-event=DemSatellite_0InternalBehavior/GetEventUdsStatus, operation=EvtInfo_DTC_0xc10387.GetEventUdsStatus
        OpEventGetEventUdsStatus_GetEventUdsStatus_Event_DTC_0xc10387: start-on-event=DemSatellite_0InternalBehavior/GetEventUdsStatus, operation=Event_DTC_0xc10387.GetEventUdsStatus
        OpEventGetEventUdsStatus_GetEventUdsStatus_EvtInfo_DTC_0x114892: start-on-event=DemSatellite_0InternalBehavior/GetEventUdsStatus, operation=EvtInfo_DTC_0x114892.GetEventUdsStatus
        OpEventGetEventUdsStatus_GetEventUdsStatus_Event_DTC_0x114892: start-on-event=DemSatellite_0InternalBehavior/GetEventUdsStatus, operation=Event_DTC_0x114892.GetEventUdsStatus
        OpEventGetEventUdsStatus_GetEventUdsStatus_EvtInfo_DTC_0x114497: start-on-event=DemSatellite_0InternalBehavior/GetEventUdsStatus, operation=EvtInfo_DTC_0x114497.GetEventUdsStatus
        OpEventGetEventUdsStatus_GetEventUdsStatus_Event_DTC_0x114497: start-on-event=DemSatellite_0InternalBehavior/GetEventUdsStatus, operation=Event_DTC_0x114497.GetEventUdsStatus
        OpEventGetEventUdsStatus_GetEventUdsStatus_EvtInfo_DTC_0x110211: start-on-event=DemSatellite_0InternalBehavior/GetEventUdsStatus, operation=EvtInfo_DTC_0x110211.GetEventUdsStatus
        OpEventGetEventUdsStatus_GetEventUdsStatus_Event_DTC_0x110211: start-on-event=DemSatellite_0InternalBehavior/GetEventUdsStatus, operation=Event_DTC_0x110211.GetEventUdsStatus
        OpEventGetEventUdsStatus_GetEventUdsStatus_EvtInfo_DTC_0x114097: start-on-event=DemSatellite_0InternalBehavior/GetEventUdsStatus, operation=EvtInfo_DTC_0x114097.GetEventUdsStatus
        OpEventGetEventUdsStatus_GetEventUdsStatus_Event_DTC_0x114097: start-on-event=DemSatellite_0InternalBehavior/GetEventUdsStatus, operation=Event_DTC_0x114097.GetEventUdsStatus
        OpEventGetEventUdsStatus_GetEventUdsStatus_EvtInfo_DTC_0x115816: start-on-event=DemSatellite_0InternalBehavior/GetEventUdsStatus, operation=EvtInfo_DTC_0x115816.GetEventUdsStatus
        OpEventGetEventUdsStatus_GetEventUdsStatus_Event_DTC_0x115816: start-on-event=DemSatellite_0InternalBehavior/GetEventUdsStatus, operation=Event_DTC_0x115816.GetEventUdsStatus
        OpEventGetEventUdsStatus_GetEventUdsStatus_EvtInfo_DTC_0x110b1e: start-on-event=DemSatellite_0InternalBehavior/GetEventUdsStatus, operation=EvtInfo_DTC_0x110b1e.GetEventUdsStatus
        OpEventGetEventUdsStatus_GetEventUdsStatus_Event_DTC_0x110b1e: start-on-event=DemSatellite_0InternalBehavior/GetEventUdsStatus, operation=Event_DTC_0x110b1e.GetEventUdsStatus
        OpEventGetEventUdsStatus_GetEventUdsStatus_EvtInfo_DTC_0x113597: start-on-event=DemSatellite_0InternalBehavior/GetEventUdsStatus, operation=EvtInfo_DTC_0x113597.GetEventUdsStatus
        OpEventGetEventUdsStatus_GetEventUdsStatus_Event_DTC_0x113597: start-on-event=DemSatellite_0InternalBehavior/GetEventUdsStatus, operation=Event_DTC_0x113597.GetEventUdsStatus
        OpEventGetEventUdsStatus_GetEventUdsStatus_EvtInfo_DTC_0x908017: start-on-event=DemSatellite_0InternalBehavior/GetEventUdsStatus, operation=EvtInfo_DTC_0x908017.GetEventUdsStatus
        OpEventGetEventUdsStatus_GetEventUdsStatus_Event_DTC_0x908017: start-on-event=DemSatellite_0InternalBehavior/GetEventUdsStatus, operation=Event_DTC_0x908017.GetEventUdsStatus
        OpEventGetEventUdsStatus_GetEventUdsStatus_EvtInfo_DTC_0x113997: start-on-event=DemSatellite_0InternalBehavior/GetEventUdsStatus, operation=EvtInfo_DTC_0x113997.GetEventUdsStatus
        OpEventGetEventUdsStatus_GetEventUdsStatus_Event_DTC_0x113997: start-on-event=DemSatellite_0InternalBehavior/GetEventUdsStatus, operation=Event_DTC_0x113997.GetEventUdsStatus
        OpEventGetEventUdsStatus_GetEventUdsStatus_EvtInfo_DTC_0x11591e: start-on-event=DemSatellite_0InternalBehavior/GetEventUdsStatus, operation=EvtInfo_DTC_0x11591e.GetEventUdsStatus
        OpEventGetEventUdsStatus_GetEventUdsStatus_Event_DTC_0x11591e: start-on-event=DemSatellite_0InternalBehavior/GetEventUdsStatus, operation=Event_DTC_0x11591e.GetEventUdsStatus
        OpEventGetEventUdsStatus_GetEventUdsStatus_EvtInfo_DTC_0x115492: start-on-event=DemSatellite_0InternalBehavior/GetEventUdsStatus, operation=EvtInfo_DTC_0x115492.GetEventUdsStatus
        OpEventGetEventUdsStatus_GetEventUdsStatus_Event_DTC_0x115492: start-on-event=DemSatellite_0InternalBehavior/GetEventUdsStatus, operation=Event_DTC_0x115492.GetEventUdsStatus
        OpEventGetEventUdsStatus_GetEventUdsStatus_EvtInfo_DTC_0xc11087: start-on-event=DemSatellite_0InternalBehavior/GetEventUdsStatus, operation=EvtInfo_DTC_0xc11087.GetEventUdsStatus
        OpEventGetEventUdsStatus_GetEventUdsStatus_Event_DTC_0xc11087: start-on-event=DemSatellite_0InternalBehavior/GetEventUdsStatus, operation=Event_DTC_0xc11087.GetEventUdsStatus
        OpEventGetEventUdsStatus_GetEventUdsStatus_EvtInfo_DTC_0x113197: start-on-event=DemSatellite_0InternalBehavior/GetEventUdsStatus, operation=EvtInfo_DTC_0x113197.GetEventUdsStatus
        OpEventGetEventUdsStatus_GetEventUdsStatus_Event_DTC_0x113197: start-on-event=DemSatellite_0InternalBehavior/GetEventUdsStatus, operation=Event_DTC_0x113197.GetEventUdsStatus
        OpEventGetEventUdsStatus_GetEventUdsStatus_EvtInfo_DTC_0x115092: start-on-event=DemSatellite_0InternalBehavior/GetEventUdsStatus, operation=EvtInfo_DTC_0x115092.GetEventUdsStatus
        OpEventGetEventUdsStatus_GetEventUdsStatus_Event_DTC_0x115092: start-on-event=DemSatellite_0InternalBehavior/GetEventUdsStatus, operation=Event_DTC_0x115092.GetEventUdsStatus
        OpEventGetEventUdsStatus_GetEventUdsStatus_EvtInfo_DTC_0xc07488: start-on-event=DemSatellite_0InternalBehavior/GetEventUdsStatus, operation=EvtInfo_DTC_0xc07488.GetEventUdsStatus
        OpEventGetEventUdsStatus_GetEventUdsStatus_Event_DTC_0xc07488: start-on-event=DemSatellite_0InternalBehavior/GetEventUdsStatus, operation=Event_DTC_0xc07488.GetEventUdsStatus
        OpEventGetEventUdsStatus_GetEventUdsStatus_EvtInfo_DTC_0x114397: start-on-event=DemSatellite_0InternalBehavior/GetEventUdsStatus, operation=EvtInfo_DTC_0x114397.GetEventUdsStatus
